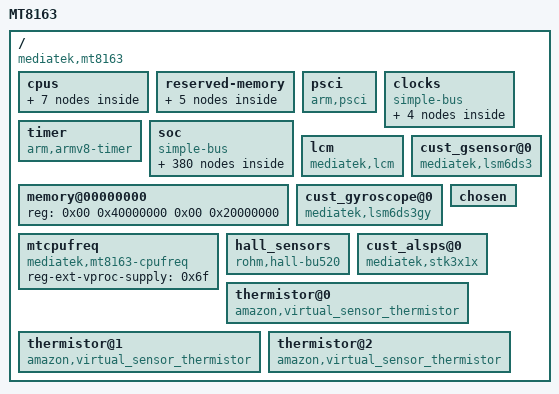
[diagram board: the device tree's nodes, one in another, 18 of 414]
/dts-v1/;

/ {
	model = "MT8163";
	compatible = "mediatek,mt8163";
	interrupt-parent = < 0x01 >;
	#address-cells = < 0x02 >;
	#size-cells = < 0x02 >;
	version = "evt";

	cpus {
		#address-cells = < 0x01 >;
		#size-cells = < 0x00 >;

		cpu@0 {
			device_type = "cpu";
			compatible = "arm,cortex-a53";
			reg = < 0x00 >;
			enable-method = "mt-boot";
			cpu-idle-states = < 0x02 0x02 0x03 0x03 0x03 >;
			cpu-release-addr = < 0x00 0x40000200 >;
			clock-frequency = "M|m";
		};

		cpu@1 {
			device_type = "cpu";
			compatible = "arm,cortex-a53";
			reg = < 0x01 >;
			enable-method = "mt-boot";
			cpu-idle-states = < 0x02 0x02 0x03 0x03 0x03 >;
			cpu-release-addr = < 0x00 0x40000200 >;
			clock-frequency = "M|m";
		};

		cpu@2 {
			device_type = "cpu";
			compatible = "arm,cortex-a53";
			reg = < 0x02 >;
			enable-method = "mt-boot";
			cpu-idle-states = < 0x02 0x02 0x03 0x03 0x03 >;
			cpu-release-addr = < 0x00 0x40000200 >;
			clock-frequency = "M|m";
		};

		cpu@3 {
			device_type = "cpu";
			compatible = "arm,cortex-a53";
			reg = < 0x03 >;
			enable-method = "mt-boot";
			cpu-idle-states = < 0x02 0x02 0x03 0x03 0x03 >;
			cpu-release-addr = < 0x00 0x40000200 >;
			clock-frequency = "M|m";
		};

		idle-states {
			entry-method = "arm,psci";

			cpu-sleep-0-0 {
				compatible = "arm,idle-state";
				arm,psci-suspend-param = < 0x10000 >;
				entry-latency-us = < 0x258 >;
				exit-latency-us = < 0x258 >;
				min-residency-us = < 0x4b0 >;
				linux,phandle = < 0x03 >;
				phandle = < 0x03 >;
			};

			cluster-sleep-0 {
				compatible = "arm,idle-state";
				arm,psci-suspend-param = < 0x2010000 >;
				entry-latency-us = < 0x320 >;
				exit-latency-us = < 0x3e8 >;
				min-residency-us = < 0x7d0 >;
				linux,phandle = < 0x02 >;
				phandle = < 0x02 >;
			};
		};
	};

	reserved-memory {
		#address-cells = < 0x02 >;
		#size-cells = < 0x02 >;
		ranges;

		mdump-reserved-memory@4bd00000 {
			compatible = "amazon,mdump-reserve-memory";
			reg = < 0x00 0x4bd00000 0x00 0x300000 >;
		};

		atf-reserved-memory@43000000 {
			compatible = "mediatek,mt8163-atf-reserved-memory";
			no-map;
			reg = < 0x00 0x43000000 0x00 0x30000 >;
		};

		ram_console-reserved-memory@44400000 {
			compatible = "mediatek,ram_console";
			reg = < 0x00 0x44400000 0x00 0x200000 >;
		};

		consys-reserve-memory {
			compatible = "mediatek,consys-reserve-memory";
			no-map;
			size = < 0x00 0x200000 >;
			alignment = < 0x00 0x200000 >;
		};

		ll_log-reserved-memory@46600000 {
			compatible = "amazon,ll_log-reserved-memory";
			reg = < 0x00 0x44600000 0x00 0x20000 >;
		};
	};

	psci {
		compatible = "arm,psci";
		method = "smc";
		cpu_suspend = < 0x84000001 >;
		cpu_off = < 0x84000002 >;
		cpu_on = < 0x84000003 >;
		affinity_info = < 0x84000004 >;
	};

	clocks {
		#address-cells = < 0x02 >;
		#size-cells = < 0x02 >;
		compatible = "simple-bus";
		ranges;

		clk_null {
			compatible = "fixed-clock";
			#clock-cells = < 0x00 >;
			clock-frequency = < 0x00 >;
			linux,phandle = < 0x3c >;
			phandle = < 0x3c >;
		};

		clk26m {
			compatible = "fixed-clock";
			#clock-cells = < 0x00 >;
			clock-frequency = < 0x18cba80 >;
			linux,phandle = < 0x31 >;
			phandle = < 0x31 >;
		};

		clk32k {
			compatible = "fixed-clock";
			#clock-cells = < 0x00 >;
			clock-frequency = < 0x7d00 >;
		};

		dummy26m {
			compatible = "fixed-clock";
			clock-frequency = < 0x18cba80 >;
			#clock-cells = < 0x00 >;
		};
	};

	timer {
		compatible = "arm,armv8-timer";
		interrupt-parent = < 0x04 >;
		interrupts = < 0x01 0x0d 0xf08 0x01 0x0e 0xf08 0x01 0x0b 0xf08 0x01 0x0a 0xf08 >;
		clock-frequency = < 0xc65d40 >;
	};

	soc {
		#address-cells = < 0x02 >;
		#size-cells = < 0x02 >;
		compatible = "simple-bus";
		ranges;

		chipid@08000000 {
			compatible = "mediatek,mt8163-chipid";
			reg = < 0x00 0x8000000 0x00 0x10 >;
		};

		topckgen@10000000 {
			compatible = "mediatek,mt8163-topckgen";
			reg = < 0x00 0x10000000 0x00 0x1000 >;
			#clock-cells = < 0x01 >;
			linux,phandle = < 0x06 >;
			phandle = < 0x06 >;
		};

		infracfg@10001000 {
			compatible = "mediatek,mt8163-infracfg\0syscon";
			reg = < 0x00 0x10001000 0x00 0x1000 >;
			#clock-cells = < 0x01 >;
			#reset-cells = < 0x01 >;
			linux,phandle = < 0x05 >;
			phandle = < 0x05 >;
		};

		syscfg_pctl_a@10005000 {
			compatible = "mediatek,mt8163-pctl-a-syscfg\0syscon";
			reg = < 0x00 0x10005000 0x00 0x1000 >;
			linux,phandle = < 0x07 >;
			phandle = < 0x07 >;
		};

		toprgu@10007000 {
			compatible = "mediatek,mt8163-rgu";
			reg = < 0x00 0x10007000 0x00 0x1000 >;
			interrupts = < 0x00 0x80 0x02 >;
			#reset-cells = < 0x01 >;
		};

		apxgpt@10008000 {
			compatible = "mediatek,mt8163-apxgpt";
			reg = < 0x00 0x10008000 0x00 0x1000 >;
			interrupts = < 0x00 0x98 0x08 >;
			clocks = < 0x05 0x06 0x05 0x46 0x06 0x60 >;
			clock-names = "bus\0clk13m\0rtc_sel";
		};

		pinctrl@10005000 {
			compatible = "mediatek,mt8163-pinctrl";
			reg = < 0x00 0x1000b000 0x00 0x1000 >;
			mediatek,pctl-regmap = < 0x07 >;
			pins-are-numbered;
			gpio-controller;
			#gpio-cells = < 0x02 >;
			interrupt-controller;
			#interrupt-cells = < 0x02 >;
			interrupts = < 0x00 0x99 0x04 0x00 0x9a 0x04 0x00 0x9b 0x04 >;
			pinctrl-names = "default";
			pinctrl-0 = < 0x08 >;
			linux,phandle = < 0x09 >;
			phandle = < 0x09 >;

			spi1 {
				linux,phandle = < 0x28 >;
				phandle = < 0x28 >;

				pins_spi {
					pinmux = < 0x3501 0x3601 0x3701 0x3801 >;
					bias-disable;
					drive-strength = < 0x08 >;
				};
			};

			uart0gpiodefault {
				linux,phandle = < 0x0b >;
				phandle = < 0x0b >;
			};

			uart0_rx_set {
				linux,phandle = < 0x0c >;
				phandle = < 0x0c >;

				pins_cmd_dat {
					pinmux = < 0x4f01 >;
				};
			};

			uart0_rx_clear {
				linux,phandle = < 0x0d >;
				phandle = < 0x0d >;

				pins_cmd_dat {
					pinmux = < 0x4f00 >;
					slew-rate = < 0x01 >;
					output-high;
				};
			};

			uart0_tx_set {
				linux,phandle = < 0x0e >;
				phandle = < 0x0e >;

				pins_cmd_dat {
					pinmux = < 0x5001 >;
				};
			};

			uart0_tx_clear {
				linux,phandle = < 0x0f >;
				phandle = < 0x0f >;

				pins_cmd_dat {
					pinmux = < 0x5000 >;
					slew-rate = < 0x01 >;
					output-high;
				};
			};

			uart1gpiodefault {
				linux,phandle = < 0x10 >;
				phandle = < 0x10 >;
			};

			uart1_rx_set {
				linux,phandle = < 0x11 >;
				phandle = < 0x11 >;

				pins_cmd_dat {
					pinmux = < 0x5101 >;
				};
			};

			uart1_rx_clear {
				linux,phandle = < 0x12 >;
				phandle = < 0x12 >;

				pins_cmd_dat {
					pinmux = < 0x5100 >;
					slew-rate = < 0x01 >;
					output-high;
				};
			};

			uart1_tx_set {
				linux,phandle = < 0x13 >;
				phandle = < 0x13 >;

				pins_cmd_dat {
					pinmux = < 0x5201 >;
				};
			};

			uart1_tx_clear {
				linux,phandle = < 0x14 >;
				phandle = < 0x14 >;

				pins_cmd_dat {
					pinmux = < 0x5200 >;
					slew-rate = < 0x01 >;
					output-high;
				};
			};

			uart2gpiodefault {
				linux,phandle = < 0x15 >;
				phandle = < 0x15 >;
			};

			uart2_rx_set {
				linux,phandle = < 0x16 >;
				phandle = < 0x16 >;

				pins_cmd_dat {
					pinmux = < 0xe01 >;
				};
			};

			uart2_rx_clear {
				linux,phandle = < 0x17 >;
				phandle = < 0x17 >;

				pins_cmd_dat {
					pinmux = < 0xe00 >;
					slew-rate = < 0x01 >;
					output-high;
				};
			};

			uart2_tx_set {
				linux,phandle = < 0x18 >;
				phandle = < 0x18 >;

				pins_cmd_dat {
					pins = < 0xf01 >;
				};
			};

			uart2_tx_clear {
				linux,phandle = < 0x19 >;
				phandle = < 0x19 >;

				pins_cmd_dat {
					pinmux = < 0xf00 >;
					slew-rate = < 0x01 >;
					output-high;
				};
			};

			uart3gpiodefault {
				linux,phandle = < 0x1a >;
				phandle = < 0x1a >;
			};

			uart3_rx_set {
				linux,phandle = < 0x1b >;
				phandle = < 0x1b >;

				pins_cmd_dat {
					pinmux = < 0x1001 >;
				};
			};

			uart3_rx_clear {
				linux,phandle = < 0x1c >;
				phandle = < 0x1c >;

				pins_cmd_dat {
					pinmux = < 0x1000 >;
					slew-rate = < 0x01 >;
					output-high;
				};
			};

			uart3_tx_set {
				linux,phandle = < 0x1d >;
				phandle = < 0x1d >;

				pins_cmd_dat {
					pinmux = < 0x1101 >;
				};
			};

			uart3_tx_clear {
				linux,phandle = < 0x1e >;
				phandle = < 0x1e >;

				pins_cmd_dat {
					pinmux = < 0x1100 >;
					slew-rate = < 0x01 >;
					output-high;
				};
			};

			pinconf_default {
				linux,phandle = < 0x08 >;
				phandle = < 0x08 >;
			};

			eint4default {
				linux,phandle = < 0x5e >;
				phandle = < 0x5e >;
			};

			eint4 {
				linux,phandle = < 0x5f >;
				phandle = < 0x5f >;

				pins_cmd_dat {
					pins = < 0x1a00 >;
					bias-disable;
				};
			};

			bq24297_int_pin {
				linux,phandle = < 0x27 >;
				phandle = < 0x27 >;

				pins_cmd_dat {
					pinmux = < 0x1700 >;
					input-enable;
					bias-pull-up;
				};
			};

			bq24297_chg_en_pin {
				linux,phandle = < 0x26 >;
				phandle = < 0x26 >;

				pins_cmd_dat {
					pins = < 0x1600 >;
					slew-rate = < 0x01 >;
					bias-disable;
					output-low;
				};
			};

			alspspincfg {
				linux,phandle = < 0x67 >;
				phandle = < 0x67 >;

				pins_cmd_dat {
					pins = < 0x3400 >;
					slew-rate = < 0x00 >;
					bias-pull-up = < 0x00 >;
				};
			};

			alspsdefaultcfg {
				linux,phandle = < 0x66 >;
				phandle = < 0x66 >;
			};

			audiodefault {
				linux,phandle = < 0x33 >;
				phandle = < 0x33 >;
			};

			audexamphigh {
				linux,phandle = < 0x38 >;
				phandle = < 0x38 >;

				pins_cmd0_dat {
					pins = < 0x1c00 >;
					slew-rate = < 0x01 >;
					output-high;
				};

				pins_cmd1_dat {
					pins = < 0x1d00 >;
					slew-rate = < 0x01 >;
					output-high;
				};
			};

			audexamplow {
				linux,phandle = < 0x39 >;
				phandle = < 0x39 >;

				pins_cmd0_dat {
					pins = < 0x1c00 >;
					slew-rate = < 0x01 >;
					output-low;
				};

				pins_cmd1_dat {
					pins = < 0x1d00 >;
					slew-rate = < 0x01 >;
					output-low;
				};
			};

			audhpamphigh {
				linux,phandle = < 0x3a >;
				phandle = < 0x3a >;

				pins_cmd_dat {
					pins = < 0x2c00 >;
					slew-rate = < 0x01 >;
					output-high;
				};
			};

			audhpamplow {
				linux,phandle = < 0x3b >;
				phandle = < 0x3b >;

				pins_cmd_dat {
					pins = < 0x2c00 >;
					slew-rate = < 0x01 >;
					output-low;
				};
			};

			audFSA8409off {
				linux,phandle = < 0x60 >;
				phandle = < 0x60 >;

				pins_cmd_dat {
					pins = < 0x1b00 >;
					slew-rate = < 0x01 >;
					output-low;
				};
			};

			audFSA8409on {
				linux,phandle = < 0x61 >;
				phandle = < 0x61 >;

				pins_cmd_dat {
					pins = < 0x1b00 >;
					slew-rate = < 0x01 >;
					output-high;
				};
			};

			audi2s1mode0 {
				linux,phandle = < 0x36 >;
				phandle = < 0x36 >;

				pins_cmd0_dat {
					pins = < 0x2e00 >;
				};

				pins_cmd1_dat {
					pins = < 0x2f00 >;
				};

				pins_cmd2_dat {
					pins = < 0x3000 >;
				};
			};

			audi2s1mode1 {
				linux,phandle = < 0x37 >;
				phandle = < 0x37 >;

				pins_cmd0_dat {
					pins = < 0x2e02 >;
				};

				pins_cmd1_dat {
					pins = < 0x2f02 >;
				};

				pins_cmd2_dat {
					pins = < 0x3002 >;
				};
			};

			pmicclkmode0 {
				linux,phandle = < 0x34 >;
				phandle = < 0x34 >;

				pins_cmd0_dat {
					pins = < 0x700 >;
				};

				pins_cmd1_dat {
					pins = < 0x800 >;
				};

				pins_cmd2_dat {
					pins = < 0x900 >;
				};
			};

			pmicclkmode1 {
				linux,phandle = < 0x35 >;
				phandle = < 0x35 >;

				pins_cmd0_dat {
					pins = < 0x701 >;
				};

				pins_cmd1_dat {
					pins = < 0x801 >;
				};

				pins_cmd2_dat {
					pins = < 0x901 >;
				};
			};

			cam0@0 {
				linux,phandle = < 0x4b >;
				phandle = < 0x4b >;

				pins_cmd_dat {
					pins = < 0x3500 >;
					slew-rate = < 0x01 >;
					output-low;
				};
			};

			cam0@1 {
				linux,phandle = < 0x4c >;
				phandle = < 0x4c >;

				pins_cmd_dat {
					pins = < 0x3500 >;
					slew-rate = < 0x01 >;
					output-high;
				};
			};

			cam0@2 {
				linux,phandle = < 0x4d >;
				phandle = < 0x4d >;

				pins_cmd_dat {
					pins = < 0x3800 >;
					slew-rate = < 0x01 >;
					output-low;
				};
			};

			cam0@3 {
				linux,phandle = < 0x4e >;
				phandle = < 0x4e >;

				pins_cmd_dat {
					pins = < 0x3800 >;
					slew-rate = < 0x01 >;
					output-high;
				};
			};

			cam1@0 {
				linux,phandle = < 0x4f >;
				phandle = < 0x4f >;

				pins_cmd_dat {
					pins = < 0x3700 >;
					slew-rate = < 0x01 >;
					output-low;
				};
			};

			cam1@1 {
				linux,phandle = < 0x50 >;
				phandle = < 0x50 >;

				pins_cmd_dat {
					pins = < 0x3700 >;
					slew-rate = < 0x01 >;
					output-high;
				};
			};

			cam1@2 {
				linux,phandle = < 0x51 >;
				phandle = < 0x51 >;

				pins_cmd_dat {
					pins = < 0x3600 >;
					slew-rate = < 0x01 >;
					output-low;
				};
			};

			cam1@3 {
				linux,phandle = < 0x52 >;
				phandle = < 0x52 >;

				pins_cmd_dat {
					pins = < 0x3600 >;
					slew-rate = < 0x01 >;
					output-high;
				};
			};

			camdefault {
				linux,phandle = < 0x4a >;
				phandle = < 0x4a >;

				pins_cmd0_dat {
					pins = < 0x7701 >;
				};

				pins_cmd1_dat {
					pins = < 0x6b02 >;
				};

				pins_cmd2_dat {
					pins = < 0x6c02 >;
				};

				pins_cmd3_dat {
					pins = < 0x6d02 >;
				};

				pins_cmd4_dat {
					pins = < 0x6e02 >;
				};

				pins_cmd5_dat {
					pins = < 0x6f02 >;
				};

				pins_cmd6_dat {
					pins = < 0x7002 >;
				};

				pins_cmd7_dat {
					pins = < 0x7102 >;
				};

				pins_cmd8_dat {
					pins = < 0x7202 >;
				};

				pins_cmd9_dat {
					pins = < 0x7302 >;
				};

				pins_cmd10_dat {
					pins = < 0x7402 >;
				};

				pins_cmd11_dat {
					pins = < 0x7801 >;
				};
			};

			default {
				linux,phandle = < 0x55 >;
				phandle = < 0x55 >;
			};

			eint0default {
				linux,phandle = < 0x62 >;
				phandle = < 0x62 >;

				pins_cmd_dat {
					pins = < 0x2300 >;
					slew-rate = < 0x00 >;
					bias-disable;
				};
			};

			eint@0 {
				linux,phandle = < 0x21 >;
				phandle = < 0x21 >;

				pins_cmd_dat {
					pins = < 0x2300 >;
					slew-rate = < 0x00 >;
					bias-disable;
				};
			};

			eintoutput0 {
				linux,phandle = < 0x20 >;
				phandle = < 0x20 >;

				pins_cmd_dat {
					pins = < 0x2300 >;
					slew-rate = < 0x01 >;
					output-low;
				};
			};

			eintoutput1 {
				linux,phandle = < 0x63 >;
				phandle = < 0x63 >;

				pins_cmd_dat {
					pins = < 0x2300 >;
					slew-rate = < 0x01 >;
					output-high;
				};
			};

			rstoutput0 {
				linux,phandle = < 0x64 >;
				phandle = < 0x64 >;

				pins_cmd_dat {
					pins = < 0x2e00 >;
					slew-rate = < 0x01 >;
					output-low;
				};
			};

			rstoutput1 {
				linux,phandle = < 0x65 >;
				phandle = < 0x65 >;

				pins_cmd_dat {
					pins = < 0x2e00 >;
					slew-rate = < 0x01 >;
					output-high;
				};
			};

			iddig_irq_init {
				linux,phandle = < 0x2b >;
				phandle = < 0x2b >;

				pins_cmd_dat {
					pins = < 0x2600 >;
					bias-pull-up;
				};
			};

			iddig_irq_low {
				linux,phandle = < 0x2c >;
				phandle = < 0x2c >;

				pins_cmd_dat {
					pins = < 0x2600 >;
					bias-pull-down;
				};
			};

			iddig_irq_high {
				linux,phandle = < 0x2d >;
				phandle = < 0x2d >;

				pins_cmd_dat {
					pins = < 0x2600 >;
					bias-pull-up;
				};
			};

			drvvbus_init {
				linux,phandle = < 0x2e >;
				phandle = < 0x2e >;

				pins_cmd_dat {
					pins = < 0x2302 >;
					slew-rate = < 0x01 >;
					bias-pull-up = < 0x00 >;
				};
			};

			drvvbus_low {
				linux,phandle = < 0x2f >;
				phandle = < 0x2f >;

				pins_cmd_dat {
					pins = < 0x2302 >;
					slew-rate = < 0x01 >;
					output-low;
				};
			};

			drvvbus_high {
				linux,phandle = < 0x30 >;
				phandle = < 0x30 >;

				pins_cmd_dat {
					pins = < 0x2302 >;
					slew-rate = < 0x01 >;
					output-high;
				};
			};

			gpslna@0 {
				linux,phandle = < 0x56 >;
				phandle = < 0x56 >;

				pins_cmd_dat {
					pinmux = < 0x600 >;
					slew-rate = < 0x00 >;
					bias-disable;
					output-low;
				};
			};

			gpslna@1 {
				linux,phandle = < 0x57 >;
				phandle = < 0x57 >;

				pins_cmd_dat {
					pinmux = < 0x600 >;
					slew-rate = < 0x01 >;
					output-high;
				};
			};

			gpslna@2 {
				linux,phandle = < 0x58 >;
				phandle = < 0x58 >;

				pins_cmd_dat {
					pinmux = < 0x600 >;
					slew-rate = < 0x01 >;
					output-low;
				};
			};

			wifireset@0 {
				linux,phandle = < 0x59 >;
				phandle = < 0x59 >;

				pins_reset_dat {
					pinmux = < 0x3c01 0x3f01 0x4001 0x4101 >;
					input-enable;
					bias-pull-up;
				};
			};

			i2c0@0 {
				linux,phandle = < 0x1f >;
				phandle = < 0x1f >;

				pins1 {
					pinmux = < 0x4b01 0x4c01 >;
					bias-disable;
				};
			};

			i2c1@0 {
				linux,phandle = < 0x24 >;
				phandle = < 0x24 >;

				pins1 {
					pinmux = < 0x3901 0x3a01 >;
					bias-disable;
				};
			};

			i2c2@0 {
				linux,phandle = < 0x25 >;
				phandle = < 0x25 >;

				pins1 {
					pinmux = < 0x4d01 0x4e01 >;
					bias-disable;
				};
			};

			lcm_gpio@43_high {
				linux,phandle = < 0x68 >;
				phandle = < 0x68 >;

				pins_cmd_dat {
					pins = < 0x2b00 >;
					slew-rate = < 0x01 >;
					output-high;
				};
			};

			lcm_gpio@43_low {
				linux,phandle = < 0x69 >;
				phandle = < 0x69 >;

				pins_cmd_dat {
					pins = < 0x2b00 >;
					slew-rate = < 0x01 >;
					output-low;
				};
			};

			lcm_gpio@83_high {
				linux,phandle = < 0x6a >;
				phandle = < 0x6a >;

				pins_cmd_dat {
					pins = < 0x5300 >;
					slew-rate = < 0x01 >;
					output-high;
				};
			};

			lcm_gpio@83_low {
				linux,phandle = < 0x6b >;
				phandle = < 0x6b >;

				pins_cmd_dat {
					pins = < 0x5300 >;
					slew-rate = < 0x01 >;
					output-low;
				};
			};

			lcm_gpio@45_high {
				linux,phandle = < 0x6c >;
				phandle = < 0x6c >;

				pins_cmd_dat {
					pins = < 0x2d00 >;
					slew-rate = < 0x01 >;
					output-high;
				};
			};

			lcm_gpio@45_low {
				linux,phandle = < 0x6d >;
				phandle = < 0x6d >;

				pins_cmd_dat {
					pins = < 0x2d00 >;
					slew-rate = < 0x01 >;
					output-low;
				};
			};

			mmc0default {
				linux,phandle = < 0x3d >;
				phandle = < 0x3d >;

				pins_cmd_dat {
					pinmux = < 0x8901 0x8801 0x8701 0x8601 0x8201 0x8101 0x8001 0x7f01 0x8401 >;
					input-enable;
					bias-pull-up;
				};

				pins_clk {
					pinmux = < 0x8501 >;
					bias-pull-down;
				};

				pins_rst {
					pinmux = < 0x8301 >;
					bias-pull-up;
				};
			};

			mmc0@0 {
				linux,phandle = < 0x3e >;
				phandle = < 0x3e >;

				pins_cmd_dat {
					pinmux = < 0x8901 0x8801 0x8701 0x8601 0x8201 0x8101 0x8001 0x7f01 0x8401 >;
					input-enable;
					drive-strength = < 0x06 >;
					bias-pull-up = < 0x65 >;
				};

				pins_clk {
					pinmux = < 0x8501 >;
					drive-strength = < 0x06 >;
					bias-pull-down = < 0x65 >;
				};

				pins_rst {
					pinmux = < 0x8301 >;
					bias-pull-up;
				};
			};

			mmc1default {
				linux,phandle = < 0x41 >;
				phandle = < 0x41 >;

				pins_cmd_dat {
					pinmux = < 0x7b01 0x7c01 0x7d01 0x7e01 0x7901 >;
					input-enable;
					drive-strength = < 0x06 >;
					bias-pull-up = < 0x65 >;
				};

				pins_clk {
					pinmux = < 0x7a01 >;
					drive-strength = < 0x06 >;
					bias-pull-down = < 0x66 >;
				};

				pins_insert {
					pinmux = < 0x3100 >;
					bias-pull-up;
				};
			};

			mmc1@0 {
				linux,phandle = < 0x42 >;
				phandle = < 0x42 >;

				pins_cmd_dat {
					pinmux = < 0x7b01 0x7c01 0x7d01 0x7e01 0x7901 >;
					input-enable;
					drive-strength = < 0x08 >;
					bias-pull-up = < 0x66 >;
				};

				pins_clk {
					pinmux = < 0x7a01 >;
					drive-strength = < 0x08 >;
					bias-pull-down = < 0x66 >;
				};
			};
		};

		dramco@10004000 {
			compatible = "mediatek,mt8163-dramco\0mediatek,dramco";
			reg = < 0x00 0x10004000 0x00 0x1000 >;
		};

		scpsys@10006000 {
			compatible = "mediatek,mt8163-scpsys\0syscon";
			#power-domain-cells = < 0x01 >;
			reg = < 0x00 0x10006000 0x00 0x1000 >;
			interrupts = < 0x00 0xa3 0x08 0x00 0xa4 0x08 0x00 0xa5 0x08 0x00 0xa6 0x08 0x00 0xa7 0x08 0x00 0xa8 0x08 0x00 0xa9 0x08 0x00 0xaa 0x08 >;
			infracfg = < 0x05 >;
			clocks = < 0x06 0x46 0x06 0x43 >;
			clock-names = "mfg\0mm";
			linux,phandle = < 0x32 >;
			phandle = < 0x32 >;
		};

		hacc@1000a000 {
			compatible = "mediatek,hacc";
			reg = < 0x00 0x1000a000 0x00 0x1000 >;
			clocks = < 0x05 0x05 >;
			clock-names = "main";
		};

		apmixedsys@1000c000 {
			compatible = "mediatek,mt8163-apmixedsys";
			reg = < 0x00 0x1000c000 0x00 0x1000 >;
			#clock-cells = < 0x01 >;
			linux,phandle = < 0x29 >;
			phandle = < 0x29 >;
		};

		fhctl@1000cf00 {
			compatible = "mediatek,mt8163-fhctl";
			reg = < 0x00 0x1000cf00 0x00 0x100 >;
		};

		pwrap@1000d000 {
			compatible = "mediatek,mt8163-pwrap";
			reg = < 0x00 0x1000d000 0x00 0x1000 >;
			reg-names = "pwrap-base";
			interrupts = < 0x00 0xa1 0x04 >;
			clocks = < 0x06 0x51 0x05 0x01 >;
			clock-names = "spi\0pwrap";

			mt6323 {
				compatible = "mediatek,mt6323";

				pmicmt6323 {
					compatible = "mediatek,mt6323-pmic";
					interrupt-parent = < 0x09 >;
					interrupts = < 0x18 0x04 >;
					log-dump-wait-time = < 0x1770 >;
				};

				regulators {
					compatible = "mediatek,mt6323-regulator";

					buck_vproc {
						regulator-name = "vproc";
						regulator-min-microvolt = < 0xaae60 >;
						regulator-max-microvolt = < 0x149970 >;
						regulator-ramp-delay = < 0x30d4 >;
						regulator-always-on;
						regulator-boot-on;
					};

					buck_vsys {
						regulator-name = "vsys";
						regulator-min-microvolt = < 0x155cc0 >;
						regulator-max-microvolt = < 0x2d95ec >;
						regulator-ramp-delay = < 0x61a8 >;
						regulator-always-on;
						regulator-boot-on;
					};

					buck_vpa {
						regulator-name = "vpa";
						regulator-min-microvolt = < 0x7a120 >;
						regulator-max-microvolt = < 0x37b1d0 >;
					};

					ldo_vtcxo {
						regulator-name = "vtcxo";
						regulator-min-microvolt = < 0x2ab980 >;
						regulator-max-microvolt = < 0x2ab980 >;
						regulator-enable-ramp-delay = < 0x5a >;
						regulator-always-on;
						regulator-boot-on;
					};

					ldo_vcn28 {
						regulator-name = "vcn28";
						regulator-min-microvolt = < 0x2ab980 >;
						regulator-max-microvolt = < 0x2ab980 >;
						regulator-enable-ramp-delay = < 0xb9 >;
						linux,phandle = < 0x5b >;
						phandle = < 0x5b >;
					};

					ldo_vcn33_bt {
						regulator-name = "vcn33_bt";
						regulator-min-microvolt = < 0x325aa0 >;
						regulator-max-microvolt = < 0x36ee80 >;
						regulator-enable-ramp-delay = < 0xb9 >;
						linux,phandle = < 0x5c >;
						phandle = < 0x5c >;
					};

					ldo_vcn33_wifi {
						regulator-name = "vcn33_wifi";
						regulator-min-microvolt = < 0x325aa0 >;
						regulator-max-microvolt = < 0x36ee80 >;
						regulator-enable-ramp-delay = < 0xb9 >;
						linux,phandle = < 0x5d >;
						phandle = < 0x5d >;
					};

					ldo_va {
						regulator-name = "va";
						regulator-min-microvolt = < 0x2ab980 >;
						regulator-max-microvolt = < 0x2ab980 >;
						regulator-enable-ramp-delay = < 0xd8 >;
						regulator-always-on;
						regulator-boot-on;
					};

					ldo_vcama {
						regulator-name = "vcama";
						regulator-min-microvolt = < 0x16e360 >;
						regulator-max-microvolt = < 0x2ab980 >;
						regulator-enable-ramp-delay = < 0xd8 >;
						linux,phandle = < 0x47 >;
						phandle = < 0x47 >;
					};

					ldo_vio28 {
						regulator-name = "vio28";
						regulator-min-microvolt = < 0x2ab980 >;
						regulator-max-microvolt = < 0x2ab980 >;
						regulator-enable-ramp-delay = < 0xd8 >;
						regulator-always-on;
						regulator-boot-on;
					};

					ldo_vusb {
						regulator-name = "vusb";
						regulator-min-microvolt = < 0x325aa0 >;
						regulator-max-microvolt = < 0x325aa0 >;
						regulator-enable-ramp-delay = < 0xd8 >;
						regulator-boot-on;
						linux,phandle = < 0x2a >;
						phandle = < 0x2a >;
					};

					ldo_vmc {
						regulator-name = "vmc";
						regulator-min-microvolt = < 0x1b7740 >;
						regulator-max-microvolt = < 0x325aa0 >;
						regulator-enable-ramp-delay = < 0x24 >;
						regulator-boot-on;
						linux,phandle = < 0x44 >;
						phandle = < 0x44 >;
					};

					ldo_vmch {
						regulator-name = "vmch";
						regulator-min-microvolt = < 0x2dc6c0 >;
						regulator-max-microvolt = < 0x325aa0 >;
						regulator-enable-ramp-delay = < 0x24 >;
						regulator-boot-on;
						linux,phandle = < 0x43 >;
						phandle = < 0x43 >;
					};

					ldo_vemc3v3 {
						regulator-name = "vemc3v3";
						regulator-min-microvolt = < 0x2dc6c0 >;
						regulator-max-microvolt = < 0x325aa0 >;
						regulator-enable-ramp-delay = < 0x24 >;
						regulator-boot-on;
						linux,phandle = < 0x3f >;
						phandle = < 0x3f >;
					};

					ldo_vgp1 {
						regulator-name = "vgp1";
						regulator-min-microvolt = < 0x124f80 >;
						regulator-max-microvolt = < 0x325aa0 >;
						regulator-enable-ramp-delay = < 0xd8 >;
					};

					ldo_vgp2 {
						regulator-name = "vgp2";
						regulator-min-microvolt = < 0x124f80 >;
						regulator-max-microvolt = < 0x2dc6c0 >;
						regulator-enable-ramp-delay = < 0xd8 >;
						linux,phandle = < 0x22 >;
						phandle = < 0x22 >;
					};

					ldo_vgp3 {
						regulator-name = "vgp3";
						regulator-min-microvolt = < 0x124f80 >;
						regulator-max-microvolt = < 0x1b7740 >;
						regulator-enable-ramp-delay = < 0xd8 >;
					};

					ldo_vcn18 {
						regulator-name = "vcn18";
						regulator-min-microvolt = < 0x1b7740 >;
						regulator-max-microvolt = < 0x1b7740 >;
						regulator-enable-ramp-delay = < 0xd8 >;
						linux,phandle = < 0x5a >;
						phandle = < 0x5a >;
					};

					ldo_vsim1 {
						regulator-name = "vsim1";
						regulator-min-microvolt = < 0x1b7740 >;
						regulator-max-microvolt = < 0x2dc6c0 >;
						regulator-enable-ramp-delay = < 0xd8 >;
					};

					ldo_vsim2 {
						regulator-name = "vsim2";
						regulator-min-microvolt = < 0x1b7740 >;
						regulator-max-microvolt = < 0x2dc6c0 >;
						regulator-enable-ramp-delay = < 0xd8 >;
					};

					ldo_vrtc {
						regulator-name = "vrtc";
						regulator-min-microvolt = < 0x2ab980 >;
						regulator-max-microvolt = < 0x2ab980 >;
						regulator-always-on;
						regulator-boot-on;
					};

					ldo_vcamaf {
						regulator-name = "vcamaf";
						regulator-min-microvolt = < 0x124f80 >;
						regulator-max-microvolt = < 0x325aa0 >;
						regulator-enable-ramp-delay = < 0xd8 >;
						linux,phandle = < 0x23 >;
						phandle = < 0x23 >;
					};

					ldo_vibr {
						regulator-name = "vibr";
						regulator-min-microvolt = < 0x124f80 >;
						regulator-max-microvolt = < 0x325aa0 >;
						regulator-enable-ramp-delay = < 0x24 >;
					};

					ldo_vrf18 {
						regulator-name = "vrf18";
						regulator-min-microvolt = < 0x1bd8e8 >;
						regulator-max-microvolt = < 0x1bd8e8 >;
						regulator-enable-ramp-delay = < 0xbb >;
						regulator-boot-on;
						linux,phandle = < 0x6e >;
						phandle = < 0x6e >;
					};

					ldo_vm {
						regulator-name = "vm";
						regulator-min-microvolt = < 0x124f80 >;
						regulator-max-microvolt = < 0x1b7740 >;
						regulator-enable-ramp-delay = < 0xd8 >;
						regulator-always-on;
						regulator-boot-on;
					};

					ldo_vio18 {
						regulator-name = "vio18";
						regulator-min-microvolt = < 0x1b7740 >;
						regulator-max-microvolt = < 0x1b7740 >;
						regulator-enable-ramp-delay = < 0xd8 >;
						regulator-always-on;
						regulator-boot-on;
						linux,phandle = < 0x40 >;
						phandle = < 0x40 >;
					};

					ldo_vcamd {
						regulator-name = "vcamd";
						regulator-min-microvolt = < 0x124f80 >;
						regulator-max-microvolt = < 0x1b7740 >;
						regulator-enable-ramp-delay = < 0xd8 >;
						linux,phandle = < 0x48 >;
						phandle = < 0x48 >;
					};

					ldo_vcamio {
						regulator-name = "vcamio";
						regulator-min-microvolt = < 0x1b7740 >;
						regulator-max-microvolt = < 0x1b7740 >;
						regulator-enable-ramp-delay = < 0xd8 >;
						linux,phandle = < 0x49 >;
						phandle = < 0x49 >;
					};
				};
			};
		};

		devapc_ao@1000e000 {
			compatible = "mediatek,mt8163-devapc_ao";
			reg = < 0x00 0x1000e000 0x00 0x1000 >;
		};

		ddrphy@1000f000 {
			compatible = "mediatek,mt8163-ddrphy\0mediatek,ddrphy";
			reg = < 0x00 0x1000f000 0x00 0x1000 >;
			clocks = < 0x05 0x36 >;
			clock-names = "dramc_f26m";
		};

		keypad@10010000 {
			compatible = "mediatek,mt8163-keypad";
			reg = < 0x00 0x10010000 0x00 0x1000 >;
			interrupts = < 0x00 0xa2 0x02 >;
			mediatek,kpd-key-debounce = < 0x400 >;
			mediatek,kpd-sw-pwrkey = < 0x74 >;
			mediatek,kpd-hw-pwrkey = < 0x08 >;
			mediatek,kpd-sw-rstkey = < 0x72 >;
			mediatek,kpd-hw-rstkey = < 0x11 >;
			mediatek,kpd-use-extend-type = < 0x00 >;
			mediatek,kpd-hw-map-num = < 0x48 >;
			mediatek,kpd-hw-init-map = < 0x73 0x00 0x00 0x00 0x00 0x00 0x00 0x00 0x00 0x00 0x00 0x00 0x00 0x00 0x00 0x00 0x00 0x00 0x00 0x00 0x00 0x00 0x00 0x00 0x00 0x00 0x00 0x00 0x00 0x00 0x00 0x00 0x00 0x00 0x00 0x00 0x00 0x00 0x00 0x00 0x00 0x00 0x00 0x00 0x00 0x00 0x00 0x00 0x00 0x00 0x00 0x00 0x00 0x00 0x00 0x00 0x00 0x00 0x00 0x00 0x00 0x00 0x00 0x00 0x00 0x00 0x00 0x00 0x00 0x00 0x00 0x00 >;
			mediatek,kpd-pwrkey-eint-gpio = < 0x00 >;
			mediatek,kpd-pwkey-gpio-din = < 0x00 >;
			mediatek,kpd-hw-dl-key0 = < 0x00 >;
			mediatek,kpd-hw-dl-key1 = < 0x11 >;
			mediatek,kpd-hw-dl-key2 = < 0x08 >;
			mediatek,kpd-hw-recovery-key = < 0x00 >;
			mediatek,kpd-hw-factory-key = < 0x11 >;
		};

		md32@10020000 {
			compatible = "mediatek,mt8163-md32";
			reg = < 0x00 0x10020000 0x00 0x38000 0x00 0x10058000 0x00 0x400 0x00 0x10059000 0x00 0x400 >;
			interrupts = < 0x00 0xae 0x04 >;
			clocks = < 0x05 0x04 >;
			clock-names = "sys";
			status = "okay";
		};

		mcucfg@10200000 {
			compatible = "mediatek,mt8173-mcucfg\0syscon";
			reg = < 0x00 0x10200000 0x00 0x1000 >;
		};

		cpuxgpt@10200000 {
			compatible = "mediatek,mt8163-cpuxgpt";
			interrupts = < 0x00 0x40 0x04 0x00 0x41 0x04 0x00 0x42 0x04 0x00 0x43 0x04 >;
		};

		lastpc@10200000 {
			compatible = "mediatek,mt8163-mcucfg";
			reg = < 0x00 0x10200000 0x00 0x200 >;
		};

		intpol-controller@10200620 {
			compatible = "mediatek,mt8163-sysirq\0mediatek,mt6577-sysirq";
			interrupt-controller;
			#interrupt-cells = < 0x03 >;
			interrupt-parent = < 0x04 >;
			reg = < 0x00 0x10200620 0x00 0x20 >;
			linux,phandle = < 0x01 >;
			phandle = < 0x01 >;
		};

		emi@10203000 {
			compatible = "mediatek,mt8163-emi\0mediatek,emi";
			reg = < 0x00 0x10203000 0x00 0x1000 >;
			interrupts = < 0x00 0x85 0x04 >;
		};

		sys_cirq@10204000 {
			compatible = "mediatek,mt8163-sys_cirq\0mediatek,mt6735-sys_cirq";
			reg = < 0x00 0x10204000 0x00 0x1000 >;
			interrupts = < 0x00 0xf0 0x08 >;
			mediatek,cirq_num = < 0xa9 >;
			mediatek,spi_start_offset = < 0x48 >;
		};

		m4u@10205000 {
			cell-index = < 0x00 >;
			compatible = "mediatek,mt8163-m4u";
			reg = < 0x00 0x10205000 0x00 0x1000 >;
			interrupts = < 0x00 0x93 0x08 >;
		};

		devapc@10207000 {
			compatible = "mediatek,mt8163-devapc";
			reg = < 0x00 0x10207000 0x00 0x1000 >;
			interrupts = < 0x00 0x85 0x08 >;
			clocks = < 0x05 0x2b >;
			clock-names = "main";
		};

		systracker@10208000 {
			compatible = "mediatek,bus_dbg-v1";
			reg = < 0x00 0x10208000 0x00 0x1000 >;
			interrupts = < 0x00 0x84 0x08 >;
		};

		dramc_nao@1020e000 {
			compatible = "mediatek,mt8163-dramc_nao\0mediatek,dramc_nao";
			reg = < 0x00 0x1020e000 0x00 0x1000 >;
		};

		gcpu@10210000 {
			compatible = "mediatek,mt8163-gcpu";
			reg = < 0x00 0x10210000 0x00 0x1000 >;
			clocks = < 0x05 0x20 >;
			clock-names = "main";
		};

		gce@10212000 {
			compatible = "mediatek,mt8163-gce";
			reg = < 0x00 0x10212000 0x00 0x1000 >;
			interrupts = < 0x00 0x8f 0x08 0x00 0x90 0x08 >;
			clocks = < 0x05 0x09 0x0a 0x00 0x0a 0x01 0x0a 0x02 0x0a 0x03 0x0a 0x04 0x0a 0x05 0x0a 0x06 0x0a 0x08 0x0a 0x07 >;
			clock-names = "MT_CG_INFRA_GCE\0MT_CG_DISP0_SMI_COMMON\0MT_CG_DISP0_SMI_LARB0\0MT_CG_DISP0_CAM_MDP\0MT_CG_DISP0_MDP_RDMA0\0MT_CG_DISP0_MDP_RSZ0\0MT_CG_DISP0_MDP_RSZ1\0MT_CG_DISP0_MDP_TDSHP0\0MT_CG_DISP0_MDP_WROT0\0MT_CG_DISP0_MDP_WDMA";
		};

		perisys_iommu@10214000 {
			cell-index = < 0x01 >;
			compatible = "mediatek,mt8163-perisys_iommu";
			reg = < 0x00 0x10214000 0x00 0x1000 >;
			interrupts = < 0x00 0x91 0x08 >;
		};

		interrupt-controller@10221000 {
			compatible = "arm,gic-400";
			interrupt-controller;
			#interrupt-cells = < 0x03 >;
			interrupt-parent = < 0x04 >;
			reg = < 0x00 0x10221000 0x00 0x1000 0x00 0x10222000 0x00 0x1000 0x00 0x10224000 0x00 0x2000 0x00 0x10226000 0x00 0x2000 >;
			interrupts = < 0x01 0x09 0xf04 >;
			linux,phandle = < 0x04 >;
			phandle = < 0x04 >;
		};

		btif_tx@11000700 {
			compatible = "mediatek,btif_tx";
			reg = < 0x00 0x11000700 0x00 0x80 >;
			interrupts = < 0x00 0x6e 0x08 >;
		};

		btif_rx@11000780 {
			compatible = "mediatek,btif_rx";
			reg = < 0x00 0x11000780 0x00 0x80 >;
			interrupts = < 0x00 0x6f 0x08 >;
		};

		auxadc@11001000 {
			compatible = "mediatek,mt8163-auxadc\0mediatek,mt6735-auxadc";
			reg = < 0x00 0x11001000 0x00 0x1000 >;
			interrupts = < 0x00 0x4c 0x02 >;
			clocks = < 0x05 0x21 >;
			clock-names = "auxadc-main";
			status = "okay";
		};

		uart0@11002000 {
			cell-index = < 0x00 >;
			compatible = "mediatek,mt8163-uart";
			reg = < 0x00 0x11002000 0x00 0x1000 0x00 0x11000300 0x00 0x1000 0x00 0x11000380 0x00 0x80 >;
			interrupts = < 0x00 0x5b 0x08 0x00 0x66 0x08 0x00 0x67 0x08 >;
			clock-frequency = < 0x18cba80 >;
			clock-div = < 0x01 >;
			clocks = < 0x05 0x13 0x05 0x29 >;
			clock-names = "uart0-main\0uart-apdma";
			pinctrl-names = "uart0_gpio_default\0uart0_rx_set\0uart0_rx_clear\0uart0_tx_set\0uart0_tx_clear";
			pinctrl-0 = < 0x0b >;
			pinctrl-1 = < 0x0c >;
			pinctrl-2 = < 0x0d >;
			pinctrl-3 = < 0x0e >;
			pinctrl-4 = < 0x0f >;
			rx_gpios = < 0x09 0x4f 0x00 >;
			tx_gpios = < 0x09 0x50 0x00 >;
			status = "okay";
		};

		uart1@11003000 {
			cell-index = < 0x01 >;
			compatible = "mediatek,mt8163-uart";
			reg = < 0x00 0x11003000 0x00 0x1000 0x00 0x11000400 0x00 0x80 0x00 0x11000480 0x00 0x80 >;
			interrupts = < 0x00 0x5c 0x08 0x00 0x68 0x08 0x00 0x69 0x08 >;
			clock-frequency = < 0x18cba80 >;
			clock-div = < 0x01 >;
			clocks = < 0x05 0x14 >;
			clock-names = "uart1-main";
			pinctrl-names = "uart1_gpio_default\0uart1_rx_set\0uart1_rx_clear\0uart1_tx_set\0uart1_tx_clear";
			pinctrl-0 = < 0x10 >;
			pinctrl-1 = < 0x11 >;
			pinctrl-2 = < 0x12 >;
			pinctrl-3 = < 0x13 >;
			pinctrl-4 = < 0x14 >;
			rx_gpios = < 0x09 0x51 0x00 >;
			tx_gpios = < 0x09 0x52 0x00 >;
			status = "disable";
		};

		uart2@11004000 {
			cell-index = < 0x02 >;
			compatible = "mediatek,mt8163-uart";
			reg = < 0x00 0x11004000 0x00 0x1000 0x00 0x11000500 0x00 0x80 0x00 0x11000580 0x00 0x80 >;
			interrupts = < 0x00 0x5d 0x08 0x00 0x6a 0x08 0x00 0x6b 0x08 >;
			clock-frequency = < 0x18cba80 >;
			clock-div = < 0x01 >;
			clocks = < 0x05 0x15 >;
			clock-names = "uart2-main";
			pinctrl-names = "uart2_gpio_default\0uart2_rx_set\0uart2_rx_clear\0uart2_tx_set\0uart2_tx_clear";
			pinctrl-0 = < 0x15 >;
			pinctrl-1 = < 0x16 >;
			pinctrl-2 = < 0x17 >;
			pinctrl-3 = < 0x18 >;
			pinctrl-4 = < 0x19 >;
			rx_gpios = < 0x09 0x0e 0x00 >;
			tx_gpios = < 0x09 0x0f 0x00 >;
			status = "disable";
		};

		uart3@11005000 {
			cell-index = < 0x03 >;
			compatible = "mediatek,mt8163-uart";
			reg = < 0x00 0x11005000 0x00 0x1000 0x00 0x11000600 0x00 0x80 0x00 0x11000680 0x00 0x80 >;
			interrupts = < 0x00 0x5e 0x08 0x00 0x6c 0x08 0x00 0x6d 0x08 >;
			clock-frequency = < 0x18cba80 >;
			clock-div = < 0x01 >;
			clocks = < 0x05 0x16 >;
			clock-names = "uart3-main";
			pinctrl-names = "uart3_gpio_default\0uart3_rx_set\0uart3_rx_clear\0uart3_tx_set\0uart3_tx_clear";
			pinctrl-0 = < 0x1a >;
			pinctrl-1 = < 0x1b >;
			pinctrl-2 = < 0x1c >;
			pinctrl-3 = < 0x1d >;
			pinctrl-4 = < 0x1e >;
			rx_gpios = < 0x09 0x10 0x00 >;
			tx_gpios = < 0x09 0x11 0x00 >;
			status = "disable";
		};

		pwm@11006000 {
			compatible = "mediatek,mt8163-pwm";
			reg = < 0x00 0x11006000 0x00 0x1000 >;
			interrupts = < 0x00 0x4d 0x08 >;
			clocks = < 0x05 0x0f 0x05 0x10 0x05 0x11 0x05 0x12 >;
			clock-names = "PWM1-main\0PWM2-main\0PWM3-main\0PWM-main";
		};

		i2c@11007000 {
			compatible = "mediatek,mt8173-i2c";
			reg = < 0x00 0x11007000 0x00 0x70 0x00 0x11000180 0x00 0x80 >;
			interrupts = < 0x00 0x54 0x08 >;
			clock-div = < 0x08 >;
			clocks = < 0x05 0x0b 0x05 0x29 >;
			clock-names = "main\0dma";
			#address-cells = < 0x01 >;
			#size-cells = < 0x00 >;
			status = "okay";
			clock-frequency = < 0x61a80 >;
			pinctrl-names = "default";
			pinctrl-0 = < 0x1f >;

			lp8557_led@2c {
				compatible = "ti,lp855x-led";
				reg = < 0x2c >;
				epprom_data = < 0x14071301 0x1105122b 0x154216a0 >;
			};

			kd_camera_hw1@3c {
				compatible = "mediatek,camera_main";
				reg = < 0x3c >;
			};

			kd_camera_hw2@21 {
				compatible = "mediatek,camera_sub";
				reg = < 0x21 >;
			};

			goodix_ts@5d {
				compatible = "goodix,gt9xx";
				reg = < 0x5d >;
				pinctrl-names = "irq_as_gpio\0irq_as_int";
				pinctrl-0 = < 0x20 >;
				pinctrl-1 = < 0x21 >;
				vdd_ana-supply = < 0x22 >;
				vcc_i2c-supply = < 0x23 >;
				goodix,rst-gpio = < 0x09 0x2e 0x00 >;
				goodix,irq-gpio = < 0x09 0x23 0x00 >;
				goodix,cfg-group0 = [ 4b 20 03 00 05 0a 35 00 02 08 2d 0f 5a 32 01 04 00 00 00 00 13 21 00 17 18 1a 14 93 33 cc 58 5a eb 17 00 00 00 22 03 1d 00 00 00 00 00 00 00 00 00 00 00 50 64 81 e2 01 14 0a 00 04 7a 51 00 7d 55 00 81 59 00 85 5d 00 8a 61 00 8a 00 00 00 00 00 00 00 00 00 00 00 00 00 00 00 00 00 00 00 00 14 00 00 00 00 00 00 00 00 00 00 00 00 00 00 00 17 16 15 14 13 12 11 10 0f 0e 0d 0c 0b 0a 09 08 07 06 05 04 03 02 01 00 ff ff ff ff ff ff 00 01 02 03 04 05 06 07 08 09 0a 0b 0c 0e 0f 10 11 12 13 15 16 17 18 19 1b 1d 1e 1f 20 21 22 23 24 25 26 27 28 29 ff ff ff ff 32 01 ];
				goodix,cfg-group2 = [ 4b 20 03 00 05 0a 35 00 02 08 2d 0f 5a 32 01 04 00 00 00 00 13 21 00 17 18 1a 14 93 33 cc 58 5a eb 17 00 00 00 22 03 1d 00 00 00 00 00 00 00 00 00 00 00 50 64 81 e2 01 14 0a 00 04 7a 51 00 7d 55 00 81 59 00 85 5d 00 8a 61 00 8a 00 00 00 00 00 00 00 00 00 00 00 00 00 00 00 00 00 00 00 00 14 00 00 00 00 00 00 00 00 00 00 00 00 00 00 00 17 16 15 14 13 12 11 10 0f 0e 0d 0c 0b 0a 09 08 07 06 05 04 03 02 01 00 ff ff ff ff ff ff 00 01 02 03 04 05 06 07 08 09 0a 0b 0c 0e 0f 10 11 12 13 15 16 17 18 19 1b 1d 1e 1f 20 21 22 23 24 25 26 27 28 29 ff ff ff ff 32 01 ];
				goodix,cfg-group3 = [ 4e 20 03 00 05 0a 35 00 02 08 20 0f 50 32 01 04 00 00 00 00 13 21 00 17 18 1a 14 93 33 cc 58 5a eb 17 00 00 00 22 03 1d 00 00 00 00 00 00 00 00 00 00 00 50 64 81 e2 01 14 0a 00 04 b7 51 00 bb 55 00 c1 59 00 c7 5d 00 cf 61 00 cf 00 00 00 00 00 00 00 00 00 00 00 00 00 00 00 00 00 00 00 00 20 00 00 00 00 00 00 00 00 00 00 00 00 00 00 00 17 16 15 14 13 12 11 10 0f 0e 0d 0c 0b 0a 09 08 07 06 05 04 03 02 01 00 ff ff ff ff ff ff 29 28 27 26 25 24 23 22 21 20 1f 1e 1d 1b 19 18 17 16 15 13 12 11 10 0f 0e 0c 0b 0a 09 08 07 06 05 04 03 02 01 00 ff ff ff ff b3 01 ];
				goodix,cfg-group5 = [ 4e 20 03 00 05 0a 35 00 02 08 20 0f 50 32 01 04 00 00 00 00 13 21 00 17 18 1a 14 93 33 cc 58 5a eb 17 00 00 00 22 03 1d 00 00 00 00 00 00 00 00 00 00 00 50 64 81 e2 01 14 0a 00 04 b7 51 00 bb 55 00 c1 59 00 c7 5d 00 cf 61 00 cf 00 00 00 00 00 00 00 00 00 00 00 00 00 00 00 00 00 00 00 00 20 00 00 00 00 00 00 00 00 00 00 00 00 00 00 00 17 16 15 14 13 12 11 10 0f 0e 0d 0c 0b 0a 09 08 07 06 05 04 03 02 01 00 ff ff ff ff ff ff 29 28 27 26 25 24 23 22 21 20 1f 1e 1d 1b 19 18 17 16 15 13 12 11 10 0f 0e 0c 0b 0a 09 08 07 06 05 04 03 02 01 00 ff ff ff ff b3 01 ];
			};
		};

		i2c@11008000 {
			compatible = "mediatek,mt8173-i2c";
			reg = < 0x00 0x11008000 0x00 0x70 0x00 0x11000200 0x00 0x80 >;
			interrupts = < 0x00 0x55 0x08 >;
			clock-div = < 0x08 >;
			clocks = < 0x05 0x0c 0x05 0x29 >;
			clock-names = "main\0dma";
			#address-cells = < 0x01 >;
			#size-cells = < 0x00 >;
			status = "okay";
			clock-frequency = < 0x61a80 >;
			pinctrl-names = "default";
			pinctrl-0 = < 0x24 >;

			sym827@60 {
				compatible = "silergy,sym827-regulator";
				reg = < 0x60 >;
				regulator-name = "vproc";
				regulator-min-microvolt = < 0x927c0 >;
				regulator-max-microvolt = < 0x152bec >;
				regulator-enable-ramp-delay = < 0x190 >;
				regulator-ramp-delay = < 0x208d >;
				regulator-always-on;
				vsel-gpio = < 0x09 0x22 0x00 >;
				linux,phandle = < 0x6f >;
				phandle = < 0x6f >;
			};
		};

		i2c@11009000 {
			compatible = "mediatek,mt8173-i2c";
			reg = < 0x00 0x11009000 0x00 0x70 0x00 0x11000280 0x00 0x80 >;
			interrupts = < 0x00 0x56 0x08 >;
			clock-div = < 0x0a >;
			clocks = < 0x05 0x0d 0x05 0x29 >;
			clock-names = "main\0dma";
			#address-cells = < 0x01 >;
			#size-cells = < 0x00 >;
			status = "okay";
			clock-frequency = < 0x61a80 >;
			pinctrl-names = "default";
			pinctrl-0 = < 0x25 >;

			bq24296@6b {
				compatible = "ti,bq24297";
				reg = < 0x6b >;
				interrupt-parent = < 0x09 >;
				interrupts = < 0x01 0x02 >;
				pinctrl-names = "bq24297_chg_en\0bq24297_interrupt_init";
				pinctrl-0 = < 0x26 >;
				pinctrl-1 = < 0x27 >;
			};

			alsps@48 {
				compatible = "mediatek,alsps";
				reg = < 0x48 >;
			};

			tmp103-sensor@70 {
				compatible = "ti,tmp103_temp_sensor";
				reg = < 0x70 >;
				tmp103-sensor,offset = < 0x8fc >;
				tmp103-sensor,alpha = < 0x0a >;
				tmp103-sensor,weight = < 0x00 >;
			};

			tmp103-sensor@71 {
				compatible = "ti,tmp103_temp_sensor";
				reg = < 0x71 >;
				tmp103-sensor,offset = < 0x2ee >;
				tmp103-sensor,alpha = < 0x0a >;
				tmp103-sensor,weight = < 0x00 >;
			};

			tmp103-sensor@72 {
				compatible = "ti,tmp103_temp_sensor";
				reg = < 0x72 >;
				tmp103-sensor,offset = < 0x2ee >;
				tmp103-sensor,alpha = < 0x0a >;
				tmp103-sensor,weight = < 0x00 >;
			};

			g_sensor@6a {
				compatible = "mediatek,g_sensor";
				reg = < 0x6a >;
			};

			gyro_sensor@6c {
				compatible = "mediatek,gyro_sensor";
				reg = < 0x6c >;
			};
		};

		spi@1100a000 {
			compatible = "mediatek,mt8163-spi";
			#address-cells = < 0x01 >;
			#size-cells = < 0x00 >;
			reg = < 0x00 0x1100a000 0x00 0x1000 >;
			interrupts = < 0x00 0x76 0x08 >;
			clocks = < 0x06 0x29 0x06 0x49 0x05 0x1b 0x05 0x41 >;
			clock-names = "parent-clk\0sel-clk\0spi-clk\0dcm-sel-clk";
			pinctrl-names = "default";
			pinctrl-0 = < 0x28 >;
			status = "disabled";
		};

		thermal@1100b000 {
			compatible = "mediatek,mt8163-thermal";
			reg = < 0x00 0x1100b000 0x00 0x1000 >;
			interrupts = < 0x00 0x4e 0x08 >;
			clocks = < 0x05 0x0a 0x05 0x21 >;
			clock-names = "therm\0auxadc";
			apmixedsys = < 0x29 >;
		};

		ptp_od@1100b000 {
			compatible = "mediatek,mt8163-ptp_od";
			reg = < 0x00 0x1100b000 0x00 0x1000 >;
			interrupts = < 0x00 0x7d 0x08 >;
			clocks = < 0x05 0x0a >;
			clock-names = "ptp_infra_therm";
		};

		btif@1100c000 {
			compatible = "mediatek,btif";
			reg = < 0x00 0x1100c000 0x00 0x1000 >;
			interrupts = < 0x00 0x70 0x08 >;
			clocks = < 0x05 0x1a 0x05 0x29 >;
			clock-names = "btifc\0apdmac";
		};

		usb@11200000 {
			compatible = "mediatek,mt8163-usb20";
			reg = < 0x00 0x11200000 0x00 0x10000 0x00 0x11210000 0x00 0x10000 >;
			interrupts = < 0x00 0x48 0x08 >;
			mode = < 0x02 >;
			multipoint = < 0x01 >;
			dyn_fifo = < 0x01 >;
			soft_con = < 0x01 >;
			dma = < 0x01 >;
			num_eps = < 0x10 >;
			dma_channels = < 0x08 >;
			clocks = < 0x29 0x02 0x05 0x17 0x05 0x07 0x05 0x08 >;
			clock-names = "usbpll\0usbmcu\0usb\0icusb";
			vusb-supply = < 0x2a >;
			pinctrl-names = "iddig_irq_init\0iddig_irq_low\0iddig_irq_high\0drvvbus_init\0drvvbus_low\0drvvbus_high";
			pinctrl-0 = < 0x2b >;
			pinctrl-1 = < 0x2c >;
			pinctrl-2 = < 0x2d >;
			pinctrl-3 = < 0x2e >;
			pinctrl-4 = < 0x2f >;
			pinctrl-5 = < 0x30 >;
			iddig_gpio = < 0x09 0x26 0x00 >;
			drvvbus_gpio = < 0x09 0x23 0x00 >;
			status = "okay";
		};

		usb@11270000 {
			compatible = "mediatek,mt8163-usb11";
			cell-index = < 0x01 >;
			reg = < 0x00 0x11270000 0x00 0x10000 0x00 0x11210000 0x00 0x10000 >;
			interrupts = < 0x00 0x49 0x08 >;
			mode = < 0x02 >;
			multipoint = < 0x01 >;
			dyn_fifo = < 0x01 >;
			soft_con = < 0x01 >;
			dma = < 0x01 >;
			num_eps = < 0x08 >;
			dma_channels = < 0x04 >;
			status = "disabled";
		};

		audiosys@11220000 {
			compatible = "mediatek,mt8163-audiosys\0syscon";
			reg = < 0x00 0x11220000 0x00 0x1000 >;
			#clock-cells = < 0x01 >;
			channel-type = < 0x00 >;
		};

		mt_soc_dl1_pcm@11220000 {
			compatible = "mediatek,mt8163-soc-pcm-dl1";
			reg = < 0x00 0x11220000 0x00 0x1000 0x00 0x11221000 0x00 0x9000 >;
			interrupts = < 0x00 0x8e 0x08 >;
			clocks = < 0x05 0x30 0x06 0x4f 0x06 0x50 0x06 0x57 0x06 0x58 0x06 0x0a 0x06 0x0b 0x31 >;
			clock-names = "aud_infra_clk\0top_mux_audio\0top_mux_audio_intbus\0aud_mux1_clk\0aud_mux2_clk\0apmixed_apll1_clk\0apmixed_apll2_clk\0top_clk26m_clk";
			audclk-gpio = < 0x07 0x00 >;
			audmiso-gpio = < 0x08 0x00 >;
			audmosi-gpio = < 0x09 0x00 >;
			extspkamp-gpio = < 0x18 0x00 >;
			i2s1clk-gpio = < 0x30 0x00 >;
			i2s1dat-gpio = < 0x2e 0x00 >;
			i2s1mclk-gpio = < 0x0f 0x00 >;
			i2s1ws-gpio = < 0x2f 0x00 >;
			power-domains = < 0x32 0x05 >;
			pinctrl-names = "default\0audpmicclk-mode0\0audpmicclk-mode1\0audi2s1-mode0\0audi2s1-mode1\0extamp-pullhigh\0extamp-pulllow\0hpamp-pullhigh\0hpamp-pulllow";
			pinctrl-0 = < 0x33 >;
			pinctrl-1 = < 0x34 >;
			pinctrl-2 = < 0x35 >;
			pinctrl-3 = < 0x36 >;
			pinctrl-4 = < 0x37 >;
			pinctrl-5 = < 0x38 >;
			pinctrl-6 = < 0x39 >;
			pinctrl-7 = < 0x3a >;
			pinctrl-8 = < 0x3b >;
			status = "okay";
		};

		mt_soc_ul1_pcm@11220000 {
			compatible = "mediatek,mt8163-soc-pcm-capture";
		};

		mt_soc_voice_md1@11220000 {
			compatible = "mediatek,mt8163-soc-pcm-voice-md1";
		};

		mt_soc_hdmi_pcm@11220000 {
			compatible = "mediatek,mt8163-soc-pcm-hdmi";
		};

		mt_soc_uldlloopback@11220000 {
			compatible = "mediatek,mt8163-soc-pcm-uldlloopback";
		};

		mt_soc_i2s0_pcm@11220000 {
			compatible = "mediatek,mt8163-soc-pcm-dl1-i2s0";
		};

		mt_soc_mrgrx_pcm@11220000 {
			compatible = "mediatek,mt8163-soc-pcm-mrgrx";
		};

		mt_soc_mrgrx_awb_pcm@11220000 {
			compatible = "mediatek,mt8163-soc-pcm-mrgrx-awb";
		};

		mt_soc_fm_i2s_pcm@11220000 {
			compatible = "mediatek,mt8163-soc-pcm-fm-i2s";
		};

		mt_soc_fm_i2s_awb_pcm@11220000 {
			compatible = "mediatek,mt8163-soc-pcm-fm-i2s-awb";
		};

		mt_soc_i2s0dl1_pcm@11220000 {
			compatible = "mediatek,mt8163-soc-pcm-dl1-i2s0Dl1";
		};

		mt_soc_dl1_awb_pcm@11220000 {
			compatible = "mediatek,mt8163-soc-pcm-dl1-awb";
		};

		mt_soc_voice_md1_bt@11220000 {
			compatible = "mediatek,mt8163-soc-pcm-voice-md1-bt";
		};

		mt_soc_voip_bt_out@11220000 {
			compatible = "mediatek,mt8163-soc-pcm-dl1-bt";
		};

		mt_soc_voip_bt_in@11220000 {
			compatible = "mediatek,mt8163-soc-pcm-bt-dai";
		};

		mt_soc_tdmrx_pcm@11220000 {
			compatible = "mediatek,mt8163-soc-tdm-capture";
		};

		mt_soc_fm_mrgtx_pcm@11220000 {
			compatible = "mediatek,mt8163-soc-pcm-fmtx";
		};

		mt_soc_ul2_pcm@11220000 {
			compatible = "mediatek,mt8163-soc-pcm-capture2";
		};

		mt_soc_i2s0_awb_pcm@11220000 {
			compatible = "mediatek,mt8163-soc-pcm-i2s0-awb";
		};

		mt_soc_voice_md2@11220000 {
			compatible = "mediatek,mt8163-soc-pcm-voice-md2";
		};

		mt_soc_routing_pcm@11220000 {
			compatible = "mediatek,mt8163-soc-pcm-routing";
		};

		mt_soc_voice_md2_bt@11220000 {
			compatible = "mediatek,mt8163-soc-pcm-voice-md2-bt";
		};

		mt_soc_hp_impedance@11220000 {
			compatible = "mediatek,mt8163-soc-pcm-hp-impedance";
		};

		mt_soc_codec_name@11220000 {
			compatible = "mediatek,mt8163-soc-codec-63xx";
		};

		mt_soc_dummy_pcm@11220000 {
			compatible = "mediatek,mt8163-soc-pcm-dummy";
		};

		mt_soc_codec_dummy_name@11220000 {
			compatible = "mediatek,mt8163-soc-codec-dummy";
		};

		mt_soc_routing_dai_name@11220000 {
			compatible = "mediatek,mt8163-soc-dai-routing";
		};

		mt_soc_dai_name@11220000 {
			compatible = "mediatek,mt8163-soc-dai-stub";
		};

		mfg@13000000 {
			compatible = "mediatek,mt8163-mfg\0mediatek,midgard-mfg";
			reg = < 0x00 0x13000000 0x00 0x1000 >;
			clocks = < 0x06 0x46 0x06 0x18 >;
			clock-names = "topck\0pll";
			power-domains = < 0x32 0x00 >;
		};

		gpu@13040000 {
			compatible = "arm,malit720\0arm,mali-t72x\0arm,malit7xx\0arm,mali-midgard";
			reg = < 0x00 0x13040000 0x00 0x4000 >;
			interrupts = < 0x00 0xe3 0x08 0x00 0xe2 0x08 0x00 0xe1 0x08 >;
			interrupt-names = "JOB\0MMU\0GPU";
			clock-frequency = < 0x1efe9200 >;
			power-domains = < 0x32 0x07 >;
		};

		mmc@11230000 {
			compatible = "mediatek,mt8163-mmc";
			reg = < 0x00 0x11230000 0x00 0x1000 >;
			interrupts = < 0x00 0x4f 0x08 >;
			infracfg = < 0x05 >;
			clocks = < 0x05 0x1c 0x05 0x1f 0x3c >;
			clock-names = "extra\0source\0hclk";
			status = "okay";
			pinctrl-names = "default\0state_uhs";
			pinctrl-0 = < 0x3d >;
			pinctrl-1 = < 0x3e >;
			bus-width = < 0x08 >;
			latch-ck = < 0x01 >;
			max-frequency = < 0xbebc200 >;
			cap-mmc-highspeed;
			mmc-hs200-1_8v;
			cap-mmc-hw-reset;
			vmmc-supply = < 0x3f >;
			vqmmc-supply = < 0x40 >;
			non-removable;
		};

		mmc@11240000 {
			compatible = "mediatek,mt8163-mmc";
			reg = < 0x00 0x11240000 0x00 0x1000 >;
			interrupts = < 0x00 0x50 0x08 >;
			clocks = < 0x05 0x1d 0x06 0x4b 0x3c >;
			clock-names = "sd_extra\0source\0hclk";
			status = "okay";
			pinctrl-names = "default\0state_uhs";
			pinctrl-0 = < 0x41 >;
			pinctrl-1 = < 0x42 >;
			bus-width = < 0x04 >;
			latch-ck = < 0x01 >;
			max-frequency = < 0xbebc200 >;
			cap-sd-highspeed;
			sd-uhs-sdr50;
			sd-uhs-sdr104;
			cd-gpios = < 0x09 0x31 0x00 >;
			vmmc-supply = < 0x43 >;
			vqmmc-supply = < 0x44 >;
		};

		mmsys@14000000 {
			compatible = "mediatek,mt8163-mmsys\0syscon";
			reg = < 0x00 0x14000000 0x00 0x1000 >;
			#clock-cells = < 0x01 >;
			linux,phandle = < 0x0a >;
			phandle = < 0x0a >;
		};

		mdp_rdma@14001000 {
			compatible = "mediatek,mt8163-mdp_rdma";
			reg = < 0x00 0x14001000 0x00 0x1000 >;
			interrupts = < 0x00 0xb2 0x08 >;
		};

		mdp_rsz0@14002000 {
			compatible = "mediatek,mt8163-mdp_rsz0";
			reg = < 0x00 0x14002000 0x00 0x1000 >;
			interrupts = < 0x00 0xb3 0x08 >;
		};

		mdp_rsz1@14003000 {
			compatible = "mediatek,mt8163-mdp_rsz1";
			reg = < 0x00 0x14003000 0x00 0x1000 >;
			interrupts = < 0x00 0xb4 0x08 >;
		};

		mdp_wdma@14004000 {
			compatible = "mediatek,mt8163-mdp_wdma";
			reg = < 0x00 0x14004000 0x00 0x1000 >;
			interrupts = < 0x00 0xb6 0x08 >;
		};

		mdp_wrot@14005000 {
			compatible = "mediatek,mt8163-mdp_wrot";
			reg = < 0x00 0x14005000 0x00 0x1000 >;
			interrupts = < 0x00 0xb7 0x08 >;
		};

		mdp_tdshp@14006000 {
			compatible = "mediatek,mt8163-mdp_tdshp0";
			reg = < 0x00 0x14006000 0x00 0x1000 >;
			interrupts = < 0x00 0xb5 0x08 >;
		};

		mt8163-dispsys {
			compatible = "mediatek,mt8163-dispsys";
		};

		disp_ovl0@14007000 {
			compatible = "mediatek,mt8163-disp_ovl0";
			reg = < 0x00 0x14007000 0x00 0x1000 >;
			interrupts = < 0x00 0xb8 0x08 >;
		};

		disp_ovl1@14008000 {
			compatible = "mediatek,mt8163-disp_ovl1";
			reg = < 0x00 0x14008000 0x00 0x1000 >;
			interrupts = < 0x00 0xb9 0x08 >;
		};

		disp_rdma0@14009000 {
			compatible = "mediatek,mt8163-disp_rdma0";
			reg = < 0x00 0x14009000 0x00 0x1000 >;
			interrupts = < 0x00 0xba 0x08 >;
		};

		disp_rdma1@1400a000 {
			compatible = "mediatek,mt8163-disp_rdma1";
			reg = < 0x00 0x1400a000 0x00 0x1000 >;
			interrupts = < 0x00 0xbb 0x08 >;
		};

		disp_wdma0@1400b000 {
			compatible = "mediatek,mt8163-disp_wdma0";
			reg = < 0x00 0x1400b000 0x00 0x1000 >;
			interrupts = < 0x00 0xbc 0x08 >;
		};

		disp_color@1400c000 {
			compatible = "mediatek,mt8163-disp_color";
			reg = < 0x00 0x1400c000 0x00 0x1000 >;
			interrupts = < 0x00 0xbd 0x08 >;
		};

		disp_ccorr@1400d000 {
			compatible = "mediatek,mt8163-disp_ccorr";
			reg = < 0x00 0x1400d000 0x00 0x1000 >;
			interrupts = < 0x00 0xbe 0x08 >;
		};

		disp_aal@1400e000 {
			compatible = "mediatek,mt8163-disp_aal";
			reg = < 0x00 0x1400e000 0x00 0x1000 >;
			interrupts = < 0x00 0xbf 0x08 >;
		};

		disp_gamma@1400f000 {
			compatible = "mediatek,mt8163-disp_gamma";
			reg = < 0x00 0x1400f000 0x00 0x1000 >;
			interrupts = < 0x00 0xc0 0x08 >;
		};

		disp_dither@14010000 {
			compatible = "mediatek,mt8163-disp_dither";
			reg = < 0x00 0x14010000 0x00 0x1000 >;
			interrupts = < 0x00 0xc1 0x08 >;
		};

		disp_ufoe@14011000 {
			compatible = "mediatek,mt8163-disp_ufoe";
			reg = < 0x00 0x14011000 0x00 0x1000 >;
		};

		disp_dsi0@14012000 {
			compatible = "mediatek,mt8163-disp_dsi0";
			reg = < 0x00 0x14012000 0x00 0x1000 >;
			interrupts = < 0x00 0xc3 0x08 >;
		};

		disp_dpi0@14013000 {
			compatible = "mediatek,mt8163-disp_dpi0";
			reg = < 0x00 0x14013000 0x00 0x1000 >;
			interrupts = < 0x00 0xc4 0x08 >;
		};

		disp_dpi1@1401c000 {
			compatible = "mediatek,mt8163-disp_dpi1";
			reg = < 0x00 0x1401c000 0x00 0x1000 >;
			interrupts = < 0x00 0xc9 0x08 >;
		};

		disp_pwm0@14014000 {
			compatible = "mediatek,mt8163-disp_pwm";
			reg = < 0x00 0x14014000 0x00 0x1000 >;
		};

		mm_mutex@14015000 {
			compatible = "mediatek,mt8163-disp_mutex";
			reg = < 0x00 0x14015000 0x00 0x1000 >;
			interrupts = < 0x00 0xb1 0x08 >;
		};

		disp_wdma1@14018000 {
			compatible = "mediatek,mt8163-disp_wdma1";
			reg = < 0x00 0x14018000 0x00 0x1000 >;
			interrupts = < 0x00 0xc6 0x08 >;
		};

		disp_config2@10206000 {
			compatible = "mediatek,mt8163-disp_config2";
			reg = < 0x00 0x10206000 0x00 0x1000 >;
		};

		disp_config3@10000000 {
			compatible = "mediatek,mt8163-disp_config3";
			reg = < 0x00 0x10000000 0x00 0x1000 >;
		};

		disp_mipi@10215000 {
			compatible = "mediatek,mt8163-disp_mipi";
			reg = < 0x00 0x10215000 0x00 0x1000 >;
		};

		disp_io_driving@10005000 {
			compatible = "mediatek,mt8163-disp_io_driving";
			reg = < 0x00 0x10005000 0x00 0x1000 >;
		};

		disp_tvdpll_cfg6@100000a0 {
			compatible = "mediatek,mt8163-disp_tvdpll_cfg6";
			reg = < 0x00 0x100000a0 0x00 0x1000 >;
		};

		disp_tvdpll_con0@1000c270 {
			compatible = "mediatek,mt8163-disp_tvdpll_con0";
			reg = < 0x00 0x1000c270 0x00 0x1000 >;
		};

		disp_tvdpll_con1@1000c274 {
			compatible = "mediatek,mt8163-disp_tvdpll_con1";
			reg = < 0x00 0x1000c274 0x00 0x1000 >;
		};

		disp_lvds_ana@10215800 {
			compatible = "mediatek,mt8163-disp_lvds_ana";
			reg = < 0x00 0x10215800 0x00 0x1000 >;
		};

		g3d_iommu@13005000 {
			cell-index = < 0x02 >;
			compatible = "mediatek,mt8163-g3d_iommu";
			reg = < 0x00 0x13005000 0x00 0x1000 >;
			interrupts = < 0x00 0xe2 0x08 >;
		};

		larb@14016000 {
			compatible = "mediatek,mt8163-smi-larb";
			reg = < 0x00 0x14016000 0x00 0x1000 >;
			interrupts = < 0x00 0xcd 0x08 >;
			mediatek,smi = < 0x45 >;
			mediatek,larbid = < 0x00 >;
			clocks = < 0x0a 0x01 0x0a 0x01 >;
			clock-names = "apb\0smi";
			power-domains = < 0x32 0x00 >;
		};

		smi@14017000 {
			compatible = "mediatek,mt8163-smi";
			reg = < 0x00 0x14017000 0x00 0x1000 >;
			clocks = < 0x0a 0x00 0x0a 0x00 >;
			clock-names = "apb\0smi";
			power-domains = < 0x32 0x00 >;
			linux,phandle = < 0x45 >;
			phandle = < 0x45 >;
		};

		disp_lvds_tx@1401b200 {
			compatible = "mediatek,mt8163-disp_lvds_tx";
			reg = < 0x00 0x1401b200 0x00 0x1000 >;
		};

		hdmi@1401d000 {
			compatible = "mediatek,mt8163-hdmitx";
			power-domains = < 0x32 0x00 >;
			reg = < 0x00 0x1401d000 0x00 0x390 0x00 0x1100f000 0x00 0x10 0x00 0x10013000 0x00 0xbc >;
			interrupts = < 0x00 0xca 0x08 >;
			clocks = < 0x05 0x25 0x05 0x26 0x0a 0x2a 0x0a 0x2d 0x0a 0x2c 0x0a 0x2b >;
			clock-names = "cec_pdn\0clk_cec_26m\0mmsys_hdmi_pll\0mmsys_hdmi_pixel\0mmsys_hdmi_audio\0mmsys_hdmi_spidif";
		};

		imgsys@15000000 {
			compatible = "mediatek,mt8163-imgsys\0syscon";
			reg = < 0x00 0x15000000 0x00 0x1000 >;
			#clock-cells = < 0x01 >;
			linux,phandle = < 0x46 >;
			phandle = < 0x46 >;
		};

		isp_display {
			compatible = "mediatek,mt8163-isp_display";
		};

		ispsys@15000000 {
			compatible = "mediatek,mt8163-ispsys";
			reg = < 0x00 0x15004000 0x00 0x9000 0x00 0x15000000 0x00 0x10000 0x00 0x10217000 0x00 0x3000 >;
			interrupts = < 0x00 0xda 0x08 0x00 0xdb 0x08 >;
			clocks = < 0x46 0x00 0x46 0x02 0x46 0x03 0x46 0x04 0x46 0x05 0x46 0x06 0x0a 0x00 >;
			clock-names = "IMG_LARB2_SMI\0IMG_CAM_SMI\0IMG_CAM_CAM\0IMG_SEN_TG\0IMG_SEN_CAM\0IMG_CAM_SV\0MM_SMI_COMMON";
		};

		larb@15001000 {
			compatible = "mediatek,mt8163-smi-larb";
			reg = < 0x00 0x15001000 0x00 0x1000 >;
			interrupts = < 0x00 0xd9 0x08 >;
			mediatek,smi = < 0x45 >;
			mediatek,larbid = < 0x02 >;
			clocks = < 0x46 0x00 0x46 0x00 >;
			clock-names = "apb\0smi";
			power-domains = < 0x32 0x03 >;
		};

		camera1@15008000 {
			compatible = "mediatek,mt8163-camera_hw";
			reg = < 0x00 0x15008000 0x00 0x1000 >;
			clocks = < 0x06 0x47 0x06 0x36 0x06 0x39 >;
			clock-names = "TOP_CAMTG_SEL\0TOP_UNIVPLL_D26\0TOP_UNIVPLL2_D2";
			reg-vcama-supply = < 0x47 >;
			reg-vcamd-supply = < 0x48 >;
			reg-vcamio-supply = < 0x49 >;
			reg-vcamaf-supply = < 0x23 >;
			reg-vcami2c-supply = < 0x40 >;
			pinctrl-names = "default\0cam0_rst0\0cam0_rst1\0cam0_pnd0\0cam0_pnd1\0cam1_rst0\0cam1_rst1\0cam1_pnd0\0cam1_pnd1\0cam_ldo0_0\0cam_ldo0_1";
			pinctrl-0 = < 0x4a >;
			pinctrl-1 = < 0x4b >;
			pinctrl-2 = < 0x4c >;
			pinctrl-3 = < 0x4d >;
			pinctrl-4 = < 0x4e >;
			pinctrl-5 = < 0x4f >;
			pinctrl-6 = < 0x50 >;
			pinctrl-7 = < 0x51 >;
			pinctrl-8 = < 0x52 >;
			status = "okay";
		};

		camera2@15008000 {
			compatible = "mediatek,mt8163-camera_hw2";
			reg = < 0x00 0x15008000 0x00 0x1000 >;
			reg-vcama-supply = < 0x47 >;
			reg-vcamd-supply = < 0x48 >;
			reg-vcamio-supply = < 0x49 >;
			reg-vcamaf-supply = < 0x23 >;
			reg-vcami2c-supply = < 0x40 >;
		};

		vdecsys@16000000 {
			compatible = "mediatek,mt8163-vdecsys\0syscon";
			reg = < 0x00 0x16000000 0x00 0x1000 >;
			#clock-cells = < 0x01 >;
			linux,phandle = < 0x53 >;
			phandle = < 0x53 >;
		};

		vdec_gcon@16000000 {
			compatible = "mediatek,mt8163-vdec_gcon";
			reg = < 0x00 0x16000000 0x00 0x10000 >;
		};

		larb@16010000 {
			compatible = "mediatek,mt8163-smi-larb";
			reg = < 0x00 0x16010000 0x00 0x10000 >;
			interrupts = < 0x00 0xd5 0x08 >;
			mediatek,smi = < 0x45 >;
			mediatek,larbid = < 0x01 >;
			clocks = < 0x53 0x00 0x53 0x01 >;
			clock-names = "apb\0smi";
			power-domains = < 0x32 0x01 >;
		};

		vdec@16020000 {
			compatible = "mediatek,mt8163-vdec";
			reg = < 0x00 0x16020000 0x00 0x10000 >;
			interrupts = < 0x00 0xd4 0x08 >;
		};

		vencsys@17000000 {
			compatible = "mediatek,mt8163-vencsys\0syscon";
			reg = < 0x00 0x17000000 0x00 0x1000 >;
			#clock-cells = < 0x01 >;
			linux,phandle = < 0x54 >;
			phandle = < 0x54 >;
		};

		larb@17001000 {
			compatible = "mediatek,mt8163-smi-larb";
			reg = < 0x00 0x17001000 0x00 0x1000 >;
			interrupts = < 0x00 0xcf 0x08 >;
			mediatek,smi = < 0x45 >;
			mediatek,larbid = < 0x03 >;
			clocks = < 0x54 0x01 0x54 0x00 >;
			clock-names = "apb\0smi";
			power-domains = < 0x32 0x02 >;
		};

		venc@17002000 {
			compatible = "mediatek,mt8163-venc";
			reg = < 0x00 0x17002000 0x00 0x1000 >;
			interrupts = < 0x00 0xce 0x08 >;
		};

		jpgenc@17003000 {
			compatible = "mediatek,mt8163-jpgenc\0mediatek,jpgenc";
			reg = < 0x00 0x17003000 0x00 0x1000 >;
			interrupts = < 0x00 0xd0 0x08 >;
			clocks = < 0x54 0x02 >;
			clock-names = "venc-jpgenc";
		};

		btcvsd@18000000 {
			compatible = "mediatek,mt8163-audio_bt_cvsd\0mediatek,audio_bt_cvsd";
			offset = < 0xf00 0x800 0xfd0 0xfd4 0xfd8 >;
			reg = < 0x00 0x10001000 0x00 0x1000 0x00 0x18000000 0x00 0x10000 0x00 0x18080000 0x00 0x8000 >;
			interrupts = < 0x00 0xec 0x08 >;
		};

		consys@18070000 {
			compatible = "mediatek,mt8163-consys";
			reg = < 0x00 0x18070000 0x00 0x200 0x00 0x10007000 0x00 0x100 0x00 0x10001000 0x00 0x1000 >;
			power-domains = < 0x32 0x04 >;
			interrupts = < 0x00 0xed 0x08 0x00 0xec 0x08 >;
			pinctrl-names = "default\0gps_lna_state_init\0gps_lna_state_oh\0gps_lna_state_ol\0wifi_reset_init";
			pinctrl-0 = < 0x55 >;
			pinctrl-1 = < 0x56 >;
			pinctrl-2 = < 0x57 >;
			pinctrl-3 = < 0x58 >;
			pinctrl-4 = < 0x59 >;
			vcn18-supply = < 0x5a >;
			vcn28-supply = < 0x5b >;
			vcn33_bt-supply = < 0x5c >;
			vcn33_wifi-supply = < 0x5d >;
			status = "okay";
		};

		wifi@180f0000 {
			compatible = "mediatek,wifi";
			reg = < 0x00 0x180f0000 0x00 0x5c >;
			interrupts = < 0x00 0xee 0x08 >;
			clocks = < 0x05 0x29 >;
			clock-names = "wifi-dma";
		};

		accdet@ {
			compatible = "mediatek,mt8163-accdet";
			interrupt-parent = < 0x09 >;
			interrupts = < 0x04 0x08 >;
			eint-debounce = < 0x3e800 >;
			accdet-gpio = < 0x09 0x1a 0x00 >;
			accdet-mic-vol = < 0x07 >;
			headset-mode-setting = < 0x500 0x200 0x01 0x1f0 0x800 0x800 0x4000 >;
			accdet-plugout-debounce = < 0x3e8 >;
			accdet-mic-mode = < 0x01 >;
			headset-three-key-threshold = < 0x00 0x50 0xdc 0x1f4 >;
			headset-four-key-threshold = < 0x00 0x3a 0x79 0xc0 0x1c2 >;
			pinctrl-names = "default\0state_eint_as_int\0typeswitchIC-off\0typeswitchIC-on";
			pinctrl-0 = < 0x5e >;
			pinctrl-1 = < 0x5f >;
			pinctrl-2 = < 0x60 >;
			pinctrl-3 = < 0x61 >;
			status = "okay";
		};

		touch@ {
			compatible = "mediatek,mt8163-touch";
			vtouch-supply = < 0x22 >;
			tpd-resolution = < 0x2d0 0x500 >;
			use-tpd-button = < 0x00 >;
			tpd-key-num = < 0x04 >;
			tpd-key-local = < 0x8b 0xac 0x9e 0x00 >;
			tpd-key-dim-local = < 0x3c 0x352 0x32 0x1e 0xb4 0x352 0x32 0x1e 0x12c 0x352 0x32 0x1e 0x1a4 0x352 0x32 0x1e >;
			tpd-max-touch-num = < 0x05 >;
			tpd-filter-enable = < 0x01 >;
			tpd-filter-pixel-density = < 0x7c >;
			tpd-filter-custom-prameters = < 0x00 0x00 0x00 0x00 0x00 0x00 0x00 0x00 0x00 0x00 0x00 0x00 >;
			tpd-filter-custom-speed = < 0x00 0x00 0x00 >;
			pinctrl-names = "default\0state_eint_as_int\0state_eint_output0\0state_eint_output1\0state_rst_output0\0state_rst_output1";
			pinctrl-0 = < 0x62 >;
			pinctrl-1 = < 0x21 >;
			pinctrl-2 = < 0x20 >;
			pinctrl-3 = < 0x63 >;
			pinctrl-4 = < 0x64 >;
			pinctrl-5 = < 0x65 >;
			status = "okay";
		};

		hwmsensor@0 {
			compatible = "mediatek,hwmsensor";
		};

		gsensor@0 {
			compatible = "mediatek,gsensor";
		};

		als_ps@0 {
			compatible = "mediatek,als_ps";
			pinctrl-names = "pin_default\0pin_cfg";
			pinctrl-0 = < 0x66 >;
			pinctrl-1 = < 0x67 >;
			status = "okay";
		};

		batchsensor@0 {
			compatible = "mediatek,batchsensor";
		};

		gyroscope@0 {
			compatible = "mediatek,gyroscope";
		};

		barometer@0 {
			compatible = "mediatek,barometer";
		};

		msensor@0 {
			compatible = "mediatek,msensor";
		};

		orientation@0 {
			compatible = "mediatek,orientation";
		};

		led@0 {
			compatible = "mediatek,red";
			led_mode = < 0x00 >;
			data;
			pwm_config = < 0x00 0x00 0x00 0x00 0x00 >;
		};

		led@1 {
			compatible = "mediatek,green";
			led_mode = < 0x00 >;
			data;
			pwm_config = < 0x00 0x00 0x00 0x00 0x00 >;
		};

		led@2 {
			compatible = "mediatek,blue";
			led_mode = < 0x00 >;
			data;
			pwm_config = < 0x00 0x00 0x00 0x00 0x00 >;
		};

		led@3 {
			compatible = "mediatek,jogball-backlight";
			led_mode = < 0x00 >;
			data;
			pwm_config = < 0x00 0x00 0x00 0x00 0x00 >;
		};

		led@4 {
			compatible = "mediatek,keyboard-backlight";
			led_mode = < 0x00 >;
			data;
			pwm_config = < 0x00 0x00 0x00 0x00 0x00 >;
		};

		led@5 {
			compatible = "mediatek,button-backlight";
			led_mode = < 0x00 >;
			data;
			pwm_config = < 0x00 0x00 0x00 0x00 0x00 >;
		};

		led@6 {
			compatible = "mediatek,lcd-backlight";
			led_mode = < 0x05 >;
			data;
			pwm_config = < 0x00 0x00 0x00 0x00 0x00 >;
			gpios = < 0x09 0x2b 0x00 >;
		};

		mtkfb@0 {
			compatible = "mediatek,MTKFB";
			clocks = < 0x0a 0x09 0x0a 0x0a 0x0a 0x0b 0x0a 0x0c 0x0a 0x0d 0x0a 0x0e 0x0a 0x17 0x0a 0x0f 0x0a 0x10 0x0a 0x11 0x0a 0x12 0x0a 0x13 0x0a 0x14 0x0a 0x20 0x0a 0x21 0x0a 0x22 0x0a 0x23 0x0a 0x24 0x0a 0x25 0x0a 0x26 0x0a 0x27 0x0a 0x28 0x0a 0x29 0x0a 0x2e 0x0a 0x2f 0x06 0x55 0x29 0x0a 0x06 0x14 0x06 0x15 0x06 0x16 0x06 0x59 0x29 0x06 0x06 0x2d 0x06 0x2e 0x06 0x2f 0x06 0x30 0x06 0x44 >;
			clock-names = "MMSYS_CLK_FAKE_ENG\0MMSYS_CLK_DISP_OVL0\0MMSYS_CLK_DISP_OVL1\0MMSYS_CLK_DISP_RDMA0\0MMSYS_CLK_DISP_RDMA1\0MMSYS_CLK_DISP_WDMA0\0MMSYS_CLK_DISP_WDMA1\0MMSYS_CLK_DISP_COLOR\0MMSYS_CLK_DISP_CCORR\0MMSYS_CLK_DISP_AAL\0MMSYS_CLK_DISP_GAMMA\0MMSYS_CLK_DISP_DITHER\0MMSYS_CLK_DISP_UFOE\0MMSYS_CLK_DISP_PWM\0MMSYS_CLK_DISP_PWM26M\0MMSYS_CLK_DSI_ENGINE\0MMSYS_CLK_DSI_DIGITAL\0MMSYS_CLK_DPI0_PIXEL\0MMSYS_CLK_DPI0_ENGINE\0MMSYS_CLK_LVDS_PIXEL\0MMSYS_CLK_LVDS_CTS\0MMSYS_CLK_DPI1_PIXEL\0MMSYS_CLK_DPI1_ENGINE\0MMSYS_CLK_DISP_DSC_ENGINE\0MMSYS_CLK_DISP_DSC_MEM\0MMSYS_CLK_MUX_DPI0_SEL\0MMSYS_APMIXED_LVDSPLL\0MMSYS_CLK_MUX_LVDSPLL_D2\0MMSYS_CLK_MUX_LVDSPLL_D4\0MMSYS_CLK_MUX_LVDSPLL_D8\0MMSYS_CLK_MUX_DPI1_SEL\0MMSYS_APMIXED_TVDPLL\0MMSYS_CLK_MUX_TVDPLL_D2\0MMSYS_CLK_MUX_TVDPLL_D4\0MMSYS_CLK_MUX_TVDPLL_D8\0MMSYS_CLK_MUX_TVDPLL_D16\0MMSYS_CLK_PWM_SEL";
		};

		ice_debug {
			compatible = "mediatek,mt8163-ice_debug\0mediatek,mt8173-ice_debug";
			clocks = < 0x05 0x2f >;
			clock-names = "ice_dbg";
		};

		bat_meter {
			compatible = "mediatek,bat_meter";
			vbat_channel_number = < 0x06 >;
			isense_channel_number = < 0x07 >;
			vbattemp_channel_number = < 0x05 >;
			vcharger_channel_number = < 0x04 >;
			swchr_power_path = < 0x01 >;
			external_swchr_support = < 0x01 >;
			r_bat_sense = < 0x04 >;
			r_i_sense = < 0x04 >;
			r_charger_1 = < 0x14a >;
			r_charger_2 = < 0x27 >;
			temperature_t0 = < 0x6e >;
			temperature_t1 = < 0x00 >;
			temperature_t1_5 = < 0x0a >;
			temperature_t2 = < 0x19 >;
			temperature_t3 = < 0x32 >;
			temperature_t = < 0xff >;
			fg_meter_resistance = < 0x00 >;
			q_max_pos_50 = < 0x1284 >;
			q_max_pos_25 = < 0x1284 >;
			q_max_pos_10 = < 0x1284 >;
			q_max_pos_0 = < 0x120c >;
			q_max_neg_10 = < 0x1068 >;
			q_max_pos_50_h_current = < 0x124d >;
			q_max_pos_25_h_current = < 0x1257 >;
			q_max_pos_10_h_current = < 0x1202 >;
			q_max_pos_0_h_current = < 0x100c >;
			q_max_neg_10_h_current = < 0x7da >;
			oam_d5 = < 0x00 >;
			change_tracking_point = < 0x01 >;
			cust_tracking_point = < 0x0e >;
			cust_r_sense = < 0xc8 >;
			cust_hw_cc = < 0x00 >;
			aging_tuning_value = < 0x64 >;
			cust_r_fg_offset = < 0x00 >;
			ocv_board_compesate = < 0x00 >;
			r_fg_board_base = < 0x3e8 >;
			r_fg_board_slope = < 0x3e8 >;
			car_tune_value = < 0x64 >;
			current_detect_r_fg = < 0x0a >;
			minerroroffset = < 0x3e8 >;
			fg_vbat_average_size = < 0x12 >;
			r_fg_value = < 0x0a >;
			cust_poweron_delta_capacity_tolrance = < 0x2d >;
			cust_poweron_low_capacity_tolrance = < 0x05 >;
			cust_poweron_max_vbat_tolrance = < 0x46 >;
			cust_poweron_delta_vbat_tolrance = < 0x3c >;
			cust_poweron_delta_hw_sw_ocv_capacity_tolrance = < 0x0a >;
			fixed_tbat_25 = < 0x00 >;
			vbat_normal_wakeup = < 0xe10 >;
			vbat_low_power_wakeup = < 0xdac >;
			normal_wakeup_period = < 0x1518 >;
			low_power_wakeup_period = < 0x12c >;
			close_poweroff_wakeup_period = < 0x1e >;
			rbat_pull_up_r = < 0xf1cc >;
			rbat_pull_down_r = < 0x1a1f8 >;
			rbat_pull_up_volt = < 0x708 >;
			step_of_qmax = < 0x3c >;
			std_loading_current = < 0x1770 >;
			q_max_pos_50_500cycle = < 0x10e0 >;
			q_max_pos_25_500cycle = < 0x10e0 >;
			q_max_pos_10_500cycle = < 0xf78 >;
			q_max_pos_0_500cycle = < 0xb40 >;
			q_max_neg_10_500cycle = < 0xb40 >;
			q_max_pos_50_h_current_500cycle = < 0x10a9 >;
			q_max_pos_25_h_current_500cycle = < 0x10b3 >;
			q_max_pos_10_h_current_500cycle = < 0xef6 >;
			q_max_pos_0_h_current_500cycle = < 0x940 >;
			q_max_neg_10_h_current_500cycle = < 0x7da >;
			batt_temperature_table_num = < 0x11 >;
			batt_temperature_table = < 0xffffffec 0x7a0bc 0xfffffff1 0x5ab90 0xfffffff6 0x440ac 0xfffffffb 0x33770 0x00 0x27420 0x05 0x1e398 0x0a 0x1771e 0x0f 0x1255c 0x14 0xe736 0x19 0xb798 0x1e 0x92d6 0x23 0x763e 0x28 0x5fdc 0x2d 0x4e34 0x32 0x402e 0x37 0x3502 0x3c 0x2c06 >;
			battery_profile_t0_num = < 0x47 >;
			battery_profile_t0 = < 0x00 0x10e3 0x01 0x10e1 0x03 0x10c6 0x04 0x10b1 0x06 0x109e 0x07 0x108d 0x09 0x107d 0x0a 0x106d 0x0b 0x105f 0x0d 0x1050 0x0e 0x1042 0x10 0x1035 0x11 0x1027 0x13 0x101a 0x14 0x100d 0x15 0x1002 0x17 0xff7 0x18 0xfeb 0x1a 0xfdd 0x1b 0xfcc 0x1d 0xfba 0x1e 0xfa9 0x1f 0xf99 0x21 0xf8c 0x22 0xf80 0x24 0xf76 0x25 0xf6d 0x27 0xf64 0x28 0xf5b 0x29 0xf51 0x2b 0xf47 0x2c 0xf3e 0x2e 0xf35 0x2f 0xf2c 0x31 0xf23 0x32 0xf1b 0x33 0xf13 0x35 0xf0c 0x36 0xf05 0x38 0xeff 0x39 0xef9 0x3b 0xef3 0x3c 0xeed 0x3d 0xee8 0x3f 0xee4 0x40 0xee0 0x42 0xedc 0x43 0xed8 0x45 0xed6 0x46 0xed3 0x47 0xed1 0x49 0xecf 0x4a 0xecc 0x4c 0xeca 0x4d 0xec8 0x4f 0xec6 0x50 0xec4 0x51 0xec1 0x53 0xebe 0x54 0xebb 0x56 0xeb8 0x57 0xeb4 0x59 0xeaf 0x5a 0xeab 0x5b 0xea6 0x5d 0xea1 0x5e 0xe9b 0x60 0xe94 0x61 0xe8e 0x63 0xe87 0x64 0xe80 >;
			battery_profile_t1_num = < 0x4e >;
			battery_profile_t1 = < 0x00 0x10db 0x01 0x10c6 0x03 0x10b5 0x04 0x10a5 0x05 0x1096 0x06 0x1088 0x08 0x107a 0x09 0x106b 0x0a 0x105e 0x0c 0x1051 0x0d 0x1044 0x0e 0x1037 0x10 0x102a 0x11 0x101d 0x12 0x1010 0x13 0x1004 0x15 0xff9 0x16 0xff0 0x17 0xfe6 0x19 0xfd9 0x1a 0xfc9 0x1b 0xfb6 0x1d 0xfa6 0x1e 0xf97 0x1f 0xf8c 0x20 0xf83 0x22 0xf7b 0x23 0xf72 0x24 0xf68 0x26 0xf5d 0x27 0xf52 0x28 0xf48 0x2a 0xf3d 0x2b 0xf32 0x2c 0xf29 0x2d 0xf20 0x2f 0xf18 0x30 0xf10 0x31 0xf09 0x33 0xf03 0x34 0xefd 0x35 0xef7 0x37 0xef2 0x38 0xeed 0x39 0xee8 0x3a 0xee3 0x3c 0xedf 0x3d 0xedb 0x3e 0xed8 0x40 0xed4 0x41 0xed1 0x42 0xece 0x44 0xecc 0x45 0xeca 0x46 0xec8 0x47 0xec6 0x49 0xec3 0x4a 0xec1 0x4b 0xebf 0x4d 0xebc 0x4e 0xeb8 0x4f 0xeb5 0x51 0xeb1 0x52 0xeac 0x53 0xea7 0x54 0xea1 0x56 0xe9a 0x57 0xe93 0x58 0xe8b 0x5a 0xe83 0x5b 0xe7c 0x5c 0xe75 0x5e 0xe72 0x5f 0xe6e 0x60 0xe68 0x61 0xe5e 0x63 0xe48 0x64 0xe1b >;
			battery_profile_t1_5_num = < 0x50 >;
			battery_profile_t1_5 = < 0x00 0x10d8 0x01 0x10c6 0x03 0x10b6 0x04 0x10a7 0x05 0x1099 0x06 0x108a 0x08 0x107c 0x09 0x106f 0x0a 0x1061 0x0b 0x1054 0x0d 0x1046 0x0e 0x103a 0x0f 0x102c 0x10 0x1020 0x12 0x1013 0x13 0x1007 0x14 0xffa 0x16 0xff0 0x17 0xfe7 0x18 0xfdd 0x19 0xfce 0x1b 0xfbd 0x1c 0xfad 0x1d 0xf9f 0x1e 0xf95 0x20 0xf8d 0x21 0xf86 0x22 0xf7d 0x23 0xf74 0x25 0xf69 0x26 0xf5e 0x27 0xf52 0x29 0xf45 0x2a 0xf3a 0x2b 0xf2f 0x2c 0xf25 0x2e 0xf1c 0x2f 0xf14 0x30 0xf0d 0x31 0xf07 0x33 0xf01 0x34 0xefb 0x35 0xef5 0x36 0xef1 0x38 0xeec 0x39 0xee7 0x3b 0xee3 0x3b 0xedf 0x3d 0xedb 0x3e 0xed7 0x3f 0xed4 0x41 0xed0 0x42 0xece 0x43 0xeca 0x44 0xec7 0x46 0xec5 0x47 0xec4 0x48 0xec1 0x49 0xebe 0x4b 0xeba 0x4c 0xeb7 0x4d 0xeb2 0x4e 0xeaf 0x50 0xeaa 0x51 0xea6 0x52 0xea0 0x54 0xe99 0x55 0xe92 0x56 0xe8b 0x57 0xe82 0x59 0xe79 0x5a 0xe73 0x5b 0xe71 0x5c 0xe6f 0x5e 0xe6c 0x5f 0xe65 0x60 0xe50 0x61 0xe1c 0x63 0xdd1 0x64 0xd5f >;
			battery_profile_t2_num = < 0x50 >;
			battery_profile_t2 = < 0x00 0x10d4 0x01 0x10c3 0x03 0x10b4 0x04 0x10a5 0x05 0x1097 0x06 0x1089 0x08 0x107b 0x09 0x106d 0x0a 0x1060 0x0b 0x1052 0x0d 0x1045 0x0e 0x1038 0x0f 0x102b 0x10 0x101e 0x12 0x1011 0x13 0x1005 0x14 0xff8 0x16 0xfed 0x17 0xfe2 0x18 0xfd7 0x19 0xfcb 0x1b 0xfbd 0x1c 0xfb0 0x1d 0xfa5 0x1e 0xf9c 0x20 0xf93 0x21 0xf8a 0x22 0xf81 0x23 0xf77 0x25 0xf6d 0x26 0xf62 0x27 0xf57 0x29 0xf4a 0x2a 0xf3d 0x2b 0xf31 0x2c 0xf26 0x2e 0xf1d 0x2f 0xf15 0x30 0xf0e 0x31 0xf07 0x33 0xf02 0x34 0xefc 0x35 0xef7 0x36 0xef1 0x38 0xeed 0x39 0xee8 0x3a 0xee4 0x3b 0xee0 0x3d 0xedc 0x3e 0xed8 0x3f 0xed4 0x41 0xed1 0x42 0xece 0x43 0xeca 0x44 0xec7 0x46 0xec4 0x47 0xec0 0x48 0xebc 0x49 0xeb7 0x4b 0xeb3 0x4c 0xeae 0x4d 0xea9 0x4e 0xea5 0x50 0xea1 0x51 0xe9c 0x52 0xe97 0x54 0xe90 0x55 0xe89 0x56 0xe82 0x57 0xe7a 0x59 0xe70 0x5a 0xe6d 0x5b 0xe6b 0x5c 0xe6a 0x5e 0xe68 0x5f 0xe61 0x60 0xe46 0x61 0xe0f 0x63 0xdc3 0x64 0xd4f >;
			battery_profile_t3_num = < 0x50 >;
			battery_profile_t3 = < 0x00 0x10d6 0x01 0x10ce 0x03 0x10be 0x04 0x10af 0x05 0x10a0 0x06 0x1092 0x08 0x1084 0x09 0x1076 0x0a 0x1068 0x0b 0x105a 0x0d 0x104d 0x0e 0x1040 0x0f 0x1033 0x10 0x1026 0x12 0x1019 0x13 0x100c 0x14 0x1000 0x16 0xff4 0x17 0xfe7 0x18 0xfdc 0x19 0xfd0 0x1b 0xfc5 0x1c 0xfba 0x1d 0xfaf 0x1e 0xfa4 0x20 0xf9a 0x21 0xf90 0x22 0xf86 0x23 0xf7c 0x25 0xf73 0x26 0xf69 0x27 0xf60 0x29 0xf55 0x2a 0xf49 0x2b 0xf3b 0x2c 0xf2e 0x2e 0xf23 0x2f 0xf1a 0x30 0xf13 0x31 0xf0c 0x33 0xf05 0x34 0xeff 0x35 0xefa 0x36 0xef4 0x38 0xeef 0x39 0xeea 0x3a 0xee5 0x3b 0xee1 0x3d 0xedd 0x3e 0xed8 0x3f 0xed5 0x41 0xed1 0x42 0xece 0x43 0xeca 0x44 0xec7 0x46 0xec3 0x47 0xebe 0x48 0xeb6 0x49 0xead 0x4b 0xea8 0x4c 0xea2 0x4d 0xe9d 0x4e 0xe98 0x50 0xe93 0x51 0xe8e 0x52 0xe8a 0x54 0xe84 0x55 0xe7d 0x56 0xe76 0x57 0xe70 0x59 0xe67 0x5a 0xe5f 0x5b 0xe5e 0x5c 0xe5d 0x5e 0xe5b 0x5f 0xe58 0x60 0xe4c 0x61 0xe22 0x63 0xde5 0x64 0xd90 >;
			r_profile_t0_num = < 0x47 >;
			r_profile_t0 = < 0x3fc 0x10e3 0x3fc 0x10e1 0x3ef 0x10c6 0x3e2 0x10b1 0x3d5 0x109e 0x3c8 0x108d 0x3bc 0x107d 0x3b3 0x106d 0x3a7 0x105f 0x39f 0x1050 0x395 0x1042 0x38d 0x1035 0x386 0x1027 0x37b 0x101a 0x375 0x100d 0x36e 0x1002 0x36c 0xff7 0x367 0xfeb 0x363 0xfdd 0x35a 0xfcc 0x34e 0xfba 0x342 0xfa9 0x339 0xf99 0x334 0xf8c 0x331 0xf80 0x32f 0xf76 0x32f 0xf6d 0x32b 0xf64 0x32c 0xf5b 0x328 0xf51 0x326 0xf47 0x324 0xf3e 0x323 0xf35 0x31f 0xf2c 0x321 0xf23 0x31f 0xf1b 0x321 0xf13 0x31f 0xf0c 0x322 0xf05 0x320 0xeff 0x322 0xef9 0x322 0xef3 0x325 0xeed 0x326 0xee8 0x329 0xee4 0x32c 0xee0 0x32f 0xedc 0x333 0xed8 0x337 0xed6 0x33d 0xed3 0x344 0xed1 0x34b 0xecf 0x352 0xecc 0x35b 0xeca 0x368 0xec8 0x377 0xec6 0x385 0xec4 0x394 0xec1 0x3a4 0xebe 0x3b5 0xebb 0x3c6 0xeb8 0x3dc 0xeb4 0x3ed 0xeaf 0x402 0xeab 0x41a 0xea6 0x42f 0xea1 0x441 0xe9b 0x45a 0xe94 0x46f 0xe8e 0x484 0xe87 0x49b 0xe80 >;
			r_profile_t1_num = < 0x4e >;
			r_profile_t1 = < 0x189 0x10db 0x189 0x10c6 0x18d 0x10b5 0x18b 0x10a5 0x18d 0x1096 0x189 0x1088 0x188 0x107a 0x184 0x106b 0x186 0x105e 0x184 0x1051 0x183 0x1044 0x183 0x1037 0x181 0x102a 0x181 0x101d 0x17f 0x1010 0x17e 0x1004 0x17e 0xff9 0x183 0xff0 0x186 0xfe6 0x184 0xfd9 0x181 0xfc9 0x177 0xfb6 0x172 0xfa6 0x16f 0xf97 0x16f 0xf8c 0x16f 0xf83 0x16f 0xf7b 0x16d 0xf72 0x16b 0xf68 0x166 0xf5d 0x161 0xf52 0x160 0xf48 0x15c 0xf3d 0x159 0xf32 0x159 0xf29 0x156 0xf20 0x15b 0xf18 0x15b 0xf10 0x157 0xf09 0x159 0xf03 0x15b 0xefd 0x15b 0xef7 0x160 0xef2 0x160 0xeed 0x163 0xee8 0x165 0xee3 0x168 0xedf 0x16a 0xedb 0x16d 0xed8 0x16f 0xed4 0x172 0xed1 0x175 0xece 0x179 0xecc 0x17c 0xeca 0x17f 0xec8 0x184 0xec6 0x189 0xec3 0x190 0xec1 0x198 0xebf 0x1a1 0xebc 0x1a7 0xeb8 0x1b1 0xeb5 0x1bd 0xeb1 0x1c7 0xeac 0x1d3 0xea7 0x1e0 0xea1 0x1ed 0xe9a 0x1fb 0xe93 0x20b 0xe8b 0x21e 0xe83 0x233 0xe7c 0x249 0xe75 0x267 0xe72 0x28d 0xe6e 0x2b9 0xe68 0x2f1 0xe5e 0x32d 0xe48 0x373 0xe1b >;
			r_profile_t1_5_num = < 0x50 >;
			r_profile_t1_5 = < 0xcb 0x10d8 0xcb 0x10c6 0xcb 0x10b6 0xcd 0x10a7 0xcd 0x1099 0xcd 0x108a 0xcb 0x107c 0xcd 0x106f 0xcd 0x1061 0xcd 0x1054 0xcd 0x1046 0xcf 0x103a 0xcf 0x102c 0xd0 0x1020 0xd0 0x1013 0xd2 0x1007 0xd0 0xffa 0xd4 0xff0 0xd9 0xfe7 0xde 0xfdd 0xda 0xfce 0xd7 0xfbd 0xd5 0xfad 0xd4 0xf9f 0xd5 0xf95 0xd7 0xf8d 0xd9 0xf86 0xd7 0xf7d 0xd7 0xf74 0xd5 0xf69 0xd2 0xf5e 0xcd 0xf52 0xc8 0xf45 0xc5 0xf3a 0xc0 0xf2f 0xbc 0xf25 0xbb 0xf1c 0xb9 0xf14 0xbb 0xf0d 0xbb 0xf07 0xbb 0xf01 0xbc 0xefb 0xbb 0xef5 0xbe 0xef1 0xbe 0xeec 0xbe 0xee7 0xc0 0xee3 0xc1 0xedf 0xc1 0xedb 0xc3 0xed7 0xc5 0xed4 0xc5 0xed0 0xc8 0xece 0xc6 0xeca 0xc6 0xec7 0xc9 0xec5 0xcd 0xec4 0xd2 0xec1 0xd4 0xebe 0xd4 0xeba 0xd5 0xeb7 0xd5 0xeb2 0xda 0xeaf 0xda 0xeaa 0xe1 0xea6 0xe4 0xea0 0xe8 0xe99 0xeb 0xe92 0xf2 0xe8b 0xf7 0xe82 0xfc 0xe79 0x102 0xe73 0x10e 0xe71 0x11b 0xe6f 0x12e 0xe6c 0x147 0xe65 0x160 0xe50 0x172 0xe1c 0x19d 0xdd1 0x1e0 0xd5f >;
			r_profile_t2_num = < 0x50 >;
			r_profile_t2 = < 0x75 0x10d4 0x75 0x10c3 0x75 0x10b4 0x75 0x10a5 0x75 0x1097 0x75 0x1089 0x75 0x107b 0x75 0x106d 0x76 0x1060 0x75 0x1052 0x76 0x1045 0x76 0x1038 0x76 0x102b 0x78 0x101e 0x78 0x1011 0x7a 0x1005 0x7a 0xff8 0x7b 0xfed 0x7d 0xfe2 0x7f 0xfd7 0x7f 0xfcb 0x7f 0xfbd 0x7f 0xfb0 0x80 0xfa5 0x82 0xf9c 0x84 0xf93 0x85 0xf8a 0x87 0xf81 0x87 0xf77 0x89 0xf6d 0x87 0xf62 0x85 0xf57 0x80 0xf4a 0x7b 0xf3d 0x78 0xf31 0x73 0xf26 0x71 0xf1d 0x70 0xf15 0x70 0xf0e 0x70 0xf07 0x71 0xf02 0x71 0xefc 0x71 0xef7 0x70 0xef1 0x71 0xeed 0x71 0xee8 0x73 0xee4 0x73 0xee0 0x73 0xedc 0x75 0xed8 0x75 0xed4 0x75 0xed1 0x76 0xece 0x75 0xeca 0x76 0xec7 0x76 0xec4 0x76 0xec0 0x75 0xebc 0x73 0xeb7 0x73 0xeb3 0x71 0xeae 0x71 0xea9 0x73 0xea5 0x73 0xea1 0x73 0xe9c 0x73 0xe97 0x75 0xe90 0x75 0xe89 0x75 0xe82 0x76 0xe7a 0x76 0xe70 0x78 0xe6d 0x78 0xe6b 0x7d 0xe6a 0x82 0xe68 0x87 0xe61 0x87 0xe46 0x8c 0xe0f 0x98 0xdc3 0xad 0xd4f >;
			r_profile_t3_num = < 0x50 >;
			r_profile_t3 = < 0x6e 0x10d6 0x6e 0x10ce 0x6d 0x10be 0x6c 0x10af 0x6c 0x10a0 0x6b 0x1092 0x6c 0x1084 0x6b 0x1076 0x6c 0x1068 0x6b 0x105a 0x6c 0x104d 0x6b 0x1040 0x6c 0x1033 0x6b 0x1026 0x6b 0x1019 0x6b 0x100c 0x6b 0x1000 0x6b 0xff4 0x6b 0xfe7 0x6c 0xfdc 0x6c 0xfd0 0x6c 0xfc5 0x6c 0xfba 0x6d 0xfaf 0x6c 0xfa4 0x6d 0xf9a 0x6e 0xf90 0x6f 0xf86 0x70 0xf7c 0x71 0xf73 0x73 0xf69 0x76 0xf60 0x76 0xf55 0x75 0xf49 0x6e 0xf3b 0x69 0xf2e 0x64 0xf23 0x62 0xf1a 0x61 0xf13 0x60 0xf0c 0x5f 0xf05 0x5f 0xeff 0x5f 0xefa 0x5f 0xef4 0x5e 0xeef 0x5e 0xeea 0x5e 0xee5 0x5e 0xee1 0x5f 0xedd 0x5e 0xed8 0x5f 0xed5 0x5f 0xed1 0x60 0xece 0x61 0xeca 0x62 0xec7 0x63 0xec3 0x65 0xebe 0x64 0xeb6 0x60 0xead 0x5f 0xea8 0x5e 0xea2 0x5f 0xe9d 0x5e 0xe98 0x5d 0xe93 0x5e 0xe8e 0x60 0xe8a 0x62 0xe84 0x61 0xe7d 0x62 0xe76 0x65 0xe70 0x60 0xe67 0x59 0xe5f 0x5a 0xe5e 0x5d 0xe5d 0x63 0xe5b 0x73 0xe58 0xa1 0xe4c 0xc4 0xe22 0xf3 0xde5 0x15e 0xd90 >;
			battery_profile_t1_500cycle = < 0x00 0x10cd 0x02 0x10b7 0x04 0x10a4 0x06 0x1092 0x08 0x1081 0x0a 0x1072 0x0d 0x1062 0x0f 0x1053 0x11 0x1045 0x13 0x1036 0x15 0x1028 0x17 0x101a 0x19 0x100c 0x1b 0x1000 0x1d 0xff5 0x1f 0xfe8 0x21 0xfda 0x23 0xfcb 0x26 0xfbb 0x28 0xfac 0x2a 0xf9e 0x2c 0xf93 0x2e 0xf89 0x30 0xf7f 0x32 0xf75 0x34 0xf69 0x36 0xf5b 0x38 0xf4c 0x3a 0xf3d 0x3c 0xf30 0x3f 0xf25 0x41 0xf1c 0x43 0xf14 0x45 0xf0d 0x47 0xf06 0x49 0xf00 0x4b 0xef9 0x4d 0xef4 0x4f 0xeee 0x51 0xeea 0x53 0xee5 0x55 0xee1 0x58 0xedd 0x5a 0xed9 0x5c 0xed6 0x5e 0xed3 0x60 0xed1 0x62 0xece 0x64 0xecc 0x66 0xec9 >;
			battery_profile_t1_5_500cycle = < 0x00 0x10cc 0x02 0x10b8 0x03 0x10a7 0x05 0x1097 0x06 0x1088 0x08 0x1079 0x09 0x106a 0x0b 0x105c 0x0c 0x104d 0x0e 0x1040 0x0f 0x1032 0x11 0x1024 0x12 0x1017 0x14 0x100a 0x15 0xffc 0x17 0xff0 0x18 0xfe6 0x1a 0xfda 0x1b 0xfcc 0x1d 0xfbc 0x1e 0xfad 0x20 0xfa0 0x21 0xf95 0x23 0xf8c 0x24 0xf83 0x26 0xf78 0x27 0xf6b 0x29 0xf5c 0x2a 0xf4a 0x2c 0xf3c 0x2d 0xf31 0x2f 0xf28 0x30 0xf1f 0x32 0xf17 0x34 0xf10 0x35 0xf09 0x37 0xf03 0x38 0xefd 0x3a 0xef7 0x3b 0xef2 0x3d 0xeec 0x3e 0xee8 0x40 0xee3 0x41 0xede 0x43 0xeda 0x44 0xed6 0x46 0xed2 0x47 0xecf 0x49 0xecc 0x4a 0xec9 0x4c 0xec6 0x4d 0xec2 0x4f 0xebe 0x50 0xeba 0x52 0xeb5 0x53 0xeb0 0x55 0xeab 0x56 0xea6 0x58 0xea1 0x59 0xe9c 0x5b 0xe95 0x5c 0xe8d 0x5e 0xe86 0x5f 0xe7d 0x61 0xe75 0x62 0xe6f 0x64 0xe6b 0x66 0xe68 >;
			battery_profile_t2_500cycle = < 0x00 0x10cd 0x01 0x10c9 0x03 0x10b9 0x04 0x10a9 0x06 0x109a 0x07 0x108c 0x08 0x107d 0x0a 0x106f 0x0b 0x1060 0x0d 0x1052 0x0e 0x1045 0x0f 0x1037 0x11 0x102a 0x12 0x101c 0x13 0x100f 0x15 0x1002 0x16 0xff6 0x18 0xfe9 0x19 0xfdd 0x1a 0xfd2 0x1c 0xfc5 0x1d 0xfb8 0x1f 0xfac 0x20 0xfa1 0x21 0xf97 0x23 0xf8e 0x24 0xf83 0x26 0xf77 0x27 0xf68 0x28 0xf55 0x2a 0xf45 0x2b 0xf3a 0x2c 0xf30 0x2e 0xf28 0x2f 0xf20 0x31 0xf19 0x32 0xf12 0x33 0xf0b 0x35 0xf05 0x36 0xeff 0x38 0xef9 0x39 0xef4 0x3a 0xeef 0x3c 0xeea 0x3d 0xee5 0x3f 0xee1 0x40 0xedc 0x41 0xed8 0x43 0xed4 0x44 0xed0 0x45 0xecc 0x47 0xec7 0x48 0xec2 0x4a 0xebc 0x4b 0xeb5 0x4c 0xeae 0x4e 0xea8 0x4f 0xea3 0x51 0xe9e 0x52 0xe9a 0x53 0xe99 0x55 0xe91 0x56 0xe89 0x58 0xe83 0x59 0xe7b 0x5a 0xe72 0x5c 0xe6b 0x5d 0xe69 0x5e 0xe67 0x60 0xe64 0x61 0xe60 0x63 0xe51 0x64 0xe1e >;
			battery_profile_t3_500cycle = < 0x00 0x10ca 0x01 0x10c0 0x03 0x10b1 0x04 0x10a2 0x06 0x1093 0x07 0x1085 0x08 0x1077 0x0a 0x1068 0x0b 0x105b 0x0d 0x104d 0x0e 0x1040 0x0f 0x1032 0x11 0x1025 0x12 0x1018 0x13 0x100b 0x15 0xfff 0x16 0xff2 0x18 0xfe6 0x19 0xfd9 0x1a 0xfce 0x1c 0xfc2 0x1d 0xfb7 0x1f 0xfac 0x20 0xfa1 0x21 0xf96 0x23 0xf8c 0x24 0xf81 0x26 0xf76 0x27 0xf67 0x28 0xf53 0x2a 0xf46 0x2b 0xf3b 0x2c 0xf31 0x2e 0xf29 0x2f 0xf22 0x31 0xf1a 0x32 0xf13 0x33 0xf0c 0x35 0xf06 0x36 0xf00 0x38 0xefa 0x39 0xef4 0x3a 0xeef 0x3c 0xeea 0x3d 0xee5 0x3f 0xee0 0x40 0xedc 0x41 0xed7 0x43 0xed3 0x44 0xecf 0x45 0xeca 0x47 0xec4 0x48 0xeb9 0x4a 0xeb0 0x4b 0xea8 0x4c 0xea2 0x4e 0xe9b 0x4f 0xe95 0x51 0xe90 0x52 0xe8b 0x53 0xe86 0x55 0xe7f 0x56 0xe78 0x58 0xe71 0x59 0xe69 0x5a 0xe60 0x5c 0xe5c 0x5d 0xe5a 0x5e 0xe58 0x60 0xe55 0x61 0xe50 0x63 0xe33 0x64 0xdfa 0x65 0xdab >;
			r_profile_t1_500cycle = < 0x27d 0x10cd 0x27d 0x10b7 0x283 0x10a4 0x284 0x1092 0x284 0x1081 0x282 0x1072 0x281 0x1062 0x280 0x1053 0x27f 0x1045 0x27e 0x1036 0x27b 0x1028 0x27b 0x101a 0x27b 0x100c 0x27b 0x1000 0x27d 0xff5 0x27b 0xfe8 0x279 0xfda 0x276 0xfcb 0x26f 0xfbb 0x26d 0xfac 0x26c 0xf9e 0x26d 0xf93 0x270 0xf89 0x270 0xf7f 0x272 0xf75 0x26e 0xf69 0x269 0xf5b 0x261 0xf4c 0x259 0xf3d 0x254 0xf30 0x251 0xf25 0x250 0xf1c 0x250 0xf14 0x252 0xf0d 0x253 0xf06 0x255 0xf00 0x257 0xef9 0x25b 0xef4 0x25d 0xeee 0x261 0xeea 0x263 0xee5 0x266 0xee1 0x26a 0xedd 0x26e 0xed9 0x273 0xed6 0x276 0xed3 0x27d 0xed1 0x283 0xece 0x289 0xecc 0x290 0xec9 >;
			r_profile_t1_5_500cycle = < 0x15c 0x10cc 0x15c 0x10b8 0x160 0x10a7 0x161 0x1097 0x161 0x1088 0x161 0x1079 0x161 0x106a 0x161 0x105c 0x160 0x104d 0x162 0x1040 0x161 0x1032 0x160 0x1024 0x160 0x1017 0x162 0x100a 0x161 0xffc 0x163 0xff0 0x165 0xfe6 0x167 0xfda 0x165 0xfcc 0x163 0xfbc 0x161 0xfad 0x161 0xfa0 0x164 0xf95 0x168 0xf8c 0x16b 0xf83 0x16c 0xf78 0x16b 0xf6b 0x164 0xf5c 0x15b 0xf4a 0x156 0xf3c 0x153 0xf31 0x152 0xf28 0x152 0xf1f 0x152 0xf17 0x154 0xf10 0x155 0xf09 0x156 0xf03 0x158 0xefd 0x15a 0xef7 0x15c 0xef2 0x15e 0xeec 0x160 0xee8 0x162 0xee3 0x164 0xede 0x167 0xeda 0x16a 0xed6 0x16d 0xed2 0x16f 0xecf 0x171 0xecc 0x175 0xec9 0x179 0xec6 0x17a 0xec2 0x17e 0xebe 0x182 0xeba 0x185 0xeb5 0x18a 0xeb0 0x18f 0xeab 0x196 0xea6 0x19d 0xea1 0x1a6 0xe9c 0x1ad 0xe95 0x1b6 0xe8d 0x1be 0xe86 0x1c7 0xe7d 0x1d0 0xe75 0x1dc 0xe6f 0x1ec 0xe6b 0x200 0xe68 >;
			r_profile_t2_500cycle = < 0xc4 0x10cd 0xc4 0x10c9 0xc3 0x10b9 0xc4 0x10a9 0xc3 0x109a 0xc4 0x108c 0xc3 0x107d 0xc3 0x106f 0xc3 0x1060 0xc3 0x1052 0xc3 0x1045 0xc3 0x1037 0xc3 0x102a 0xc2 0x101c 0xc3 0x100f 0xc2 0x1002 0xc3 0xff6 0xc3 0xfe9 0xc4 0xfdd 0xc6 0xfd2 0xc7 0xfc5 0xc7 0xfb8 0xc7 0xfac 0xc6 0xfa1 0xc8 0xf97 0xcc 0xf8e 0xd0 0xf83 0xd2 0xf77 0xd1 0xf68 0xc6 0xf55 0xbd 0xf45 0xba 0xf3a 0xb6 0xf30 0xb5 0xf28 0xb5 0xf20 0xb4 0xf19 0xb4 0xf12 0xb3 0xf0b 0xb4 0xf05 0xb5 0xeff 0xb5 0xef9 0xb5 0xef4 0xb6 0xeef 0xb6 0xeea 0xb7 0xee5 0xb8 0xee1 0xb9 0xedc 0xba 0xed8 0xba 0xed4 0xbb 0xed0 0xbc 0xecc 0xbd 0xec7 0xbd 0xec2 0xbd 0xebc 0xbd 0xeb5 0xbd 0xeae 0xbd 0xea8 0xbd 0xea3 0xbe 0xe9e 0xad 0xe9a 0xcb 0xe99 0xca 0xe91 0xcb 0xe89 0xcf 0xe83 0xd4 0xe7b 0xd0 0xe72 0xce 0xe6b 0xd3 0xe69 0xda 0xe67 0xe5 0xe64 0xff 0xe60 0x139 0xe51 0x16c 0xe1e >;
			r_profile_t3_500cycle = < 0x8c 0x10ca 0x8c 0x10c0 0x8b 0x10b1 0x8b 0x10a2 0x8c 0x1093 0x8b 0x1085 0x8b 0x1077 0x8b 0x1068 0x8b 0x105b 0x8b 0x104d 0x8b 0x1040 0x8b 0x1032 0x8b 0x1025 0x8b 0x1018 0x8b 0x100b 0x8c 0xfff 0x8b 0xff2 0x8c 0xfe6 0x8b 0xfd9 0x8d 0xfce 0x8d 0xfc2 0x8d 0xfb7 0x8e 0xfac 0x8e 0xfa1 0x90 0xf96 0x92 0xf8c 0x95 0xf81 0x99 0xf76 0x99 0xf67 0x8e 0xf53 0x88 0xf46 0x85 0xf3b 0x84 0xf31 0x84 0xf29 0x82 0xf22 0x81 0xf1a 0x82 0xf13 0x82 0xf0c 0x81 0xf06 0x81 0xf00 0x81 0xefa 0x81 0xef4 0x81 0xeef 0x81 0xeea 0x82 0xee5 0x81 0xee0 0x84 0xedc 0x83 0xed7 0x84 0xed3 0x85 0xecf 0x87 0xeca 0x89 0xec4 0x88 0xeb9 0x85 0xeb0 0x84 0xea8 0x84 0xea2 0x83 0xe9b 0x81 0xe95 0x82 0xe90 0x82 0xe8b 0x84 0xe86 0x85 0xe7f 0x85 0xe78 0x88 0xe71 0x88 0xe69 0x81 0xe60 0x7e 0xe5c 0x7f 0xe5a 0x82 0xe58 0x8b 0xe55 0xaf 0xe50 0xdf 0xe33 0x109 0xdfa 0x15c 0xdab >;
		};

		BAT_NOTIFY {
			compatible = "mediatek,bat_notify";
		};

		bat_comm {
			compatible = "mediatek,battery";
			stop_charging_in_takling = < 0x01 >;
			talking_recharge_voltage = < 0xed8 >;
			talking_sync_time = < 0x3c >;
			mtk_temperature_recharge_support = < 0x01 >;
			max_charge_temperature = < 0x3c >;
			max_charge_temperature_minus_x_degree = < 0x3c >;
			min_charge_temperature = < 0x00 >;
			min_charge_temperature_plus_x_degree = < 0x06 >;
			err_charge_temperature = < 0xff >;
			v_pre2cc_thres = < 0xd48 >;
			v_cc2topoff_thres = < 0xfd2 >;
			recharging_voltage = < 0x100e >;
			charging_full_current = < 0x64 >;
			config_usb_if = < 0x00 >;
			usb_charger_current_suspend = < 0x00 >;
			usb_charger_current_unconfigured = < 0x1b58 >;
			usb_charger_current_configured = < 0xc350 >;
			usb_charger_current = < 0xc350 >;
			ac_charger_current = < 0x186a0 >;
			non_std_ac_charger_current = < 0x186a0 >;
			charging_host_charger_current = < 0xc350 >;
			apple_0_5a_charger_current = < 0xc350 >;
			apple_1_0a_charger_current = < 0x186a0 >;
			apple_2_1a_charger_current = < 0x33450 >;
			bat_low_temp_protect_enable = < 0x00 >;
			v_charger_enable = < 0x00 >;
			v_charger_max = < 0x1964 >;
			v_charger_min = < 0x1130 >;
			onehundred_percent_tracking_time = < 0x0a >;
			npercent_tracking_time = < 0x14 >;
			sync_to_real_tracking_time = < 0x3c >;
			v_0percent_tracking = < 0xd48 >;
			system_off_voltage = < 0xd48 >;
			high_battery_voltage_support = < 0x01 >;
			mtk_jeita_standard_support = < 0x01 >;
			cust_soc_jeita_sync_time = < 0x3c >;
			jeita_temp_below_neg_10_cv_voltage = < 0x426030 >;
			jeita_temp_neg_10_to_pos_0_cv_voltage = < 0x426030 >;
			jeita_temp_pos_0_to_pos_10_cv_voltage = < 0x426030 >;
			jeita_temp_pos_10_to_pos_45_cv_voltage = < 0x426030 >;
			jeita_temp_pos_45_to_pos_60_cv_voltage = < 0x3e8fa0 >;
			jeita_temp_above_pos_60_cv_voltage = < 0x3e8fa0 >;
		};

		flashlight@ {
			compatible = "mediatek,camera_flashlight";
		};

		isp_pipemgr {
			compatible = "mediatek,mt8163-isp_pipemgr";
		};

		isp_sysram {
			compatible = "mediatek,mt8163-isp_sysram";
		};

		mtee {
			compatible = "mediatek,mtee";
		};
	};

	lcm {
		compatible = "mediatek,lcm";
		pinctrl-names = "default\0lcm_pwr_high\0lcm_pwr_low\0lcm_rst_high\0lcm_rst_low\0lcm_pwr_n_high\0lcm_pwr_n_low";
		pinctrl-0 = < 0x55 >;
		pinctrl-1 = < 0x68 >;
		pinctrl-2 = < 0x69 >;
		pinctrl-3 = < 0x6a >;
		pinctrl-4 = < 0x6b >;
		pinctrl-5 = < 0x6c >;
		pinctrl-6 = < 0x6d >;
		reg-lcm-supply = < 0x6e >;
	};

	memory@00000000 {
		device_type = "memory";
		reg = < 0x00 0x40000000 0x00 0x20000000 >;
	};

	cust_gsensor@0 {
		compatible = "mediatek,lsm6ds3";
		i2c_num = < 0x02 >;
		i2c_addr = < 0x6a >;
		direction = < 0x00 >;
		power_id = < 0xffff >;
		power_vol = < 0x00 >;
		firlen = < 0x00 >;
		is_batch_supported = < 0x00 >;
	};

	cust_gyroscope@0 {
		compatible = "mediatek,lsm6ds3gy";
		i2c_num = < 0x02 >;
		i2c_addr = < 0x6a >;
		direction = < 0x00 >;
		power_id = < 0xffff >;
		power_vol = < 0x00 >;
		firlen = < 0x00 >;
		is_batch_supported = < 0x00 >;
	};

	chosen {
		bootargs = "console=ttyS0,921600n1 root=/dev/ram initrd=0x44000200,0x200000";
	};

	mtcpufreq {
		compatible = "mediatek,mt8163-cpufreq";
		reg-ext-vproc-supply = < 0x6f >;
	};

	hall_sensors {
		compatible = "rohm,hall-bu520";
		interrupt-parent = < 0x09 >;
		interrupts = < 0x13 0x08 >;
		int-gpio = < 0x09 0x33 0x00 >;
		sensor-name = "hall_sensor_1";
		sensor-num = < 0x01 >;
	};

	cust_alsps@0 {
		compatible = "mediatek,stk3x1x";
		i2c_num = < 0x02 >;
		i2c_addr = < 0x48 >;
		polling_mode_ps = < 0x00 >;
		polling_mode_als = < 0x01 >;
		power_id = < 0xffff >;
		power_vol = < 0x00 >;
		als_level = < 0x00 0x101 0x27d 0x403 0x8f9 0x15d4 0x1a4a 0x2c25 0x4fe1 0x64a8 0x7992 0xb1f0 0xe251 0xe251 0xe251 >;
		als_value = < 0x00 0x84 0x130 0x1f6 0x3ec 0x7d3 0xbbe 0x138e 0x1f44 0x2710 0x2ee0 0x3e80 0x4e20 0x4e20 0x4e20 0x4e20 >;
		ps_threshold_high = < 0x46 >;
		ps_threshold_low = < 0x28 >;
		is_batch_supported_ps = < 0x01 >;
	};

	thermistor@0 {
		compatible = "amazon,virtual_sensor_thermistor";
		thermistor,offset = < 0x1482 >;
		thermistor,offset.sign = "plus";
		thermistor,alpha = < 0x0a >;
		thermistor,weight = < 0xaf >;
		aux_channel_num = < 0x00 >;
	};

	thermistor@1 {
		compatible = "amazon,virtual_sensor_thermistor";
		thermistor,offset = < 0xb54 >;
		thermistor,offset.sign = "plus";
		thermistor,alpha = < 0x0a >;
		thermistor,weight = < 0xaf >;
		aux_channel_num = < 0x01 >;
	};

	thermistor@2 {
		compatible = "amazon,virtual_sensor_thermistor";
		thermistor,offset = < 0xbb8 >;
		thermistor,offset.sign = "minus";
		thermistor,alpha = < 0x0a >;
		thermistor,weight = < 0xaf >;
		aux_channel_num = < 0x02 >;
	};
};
